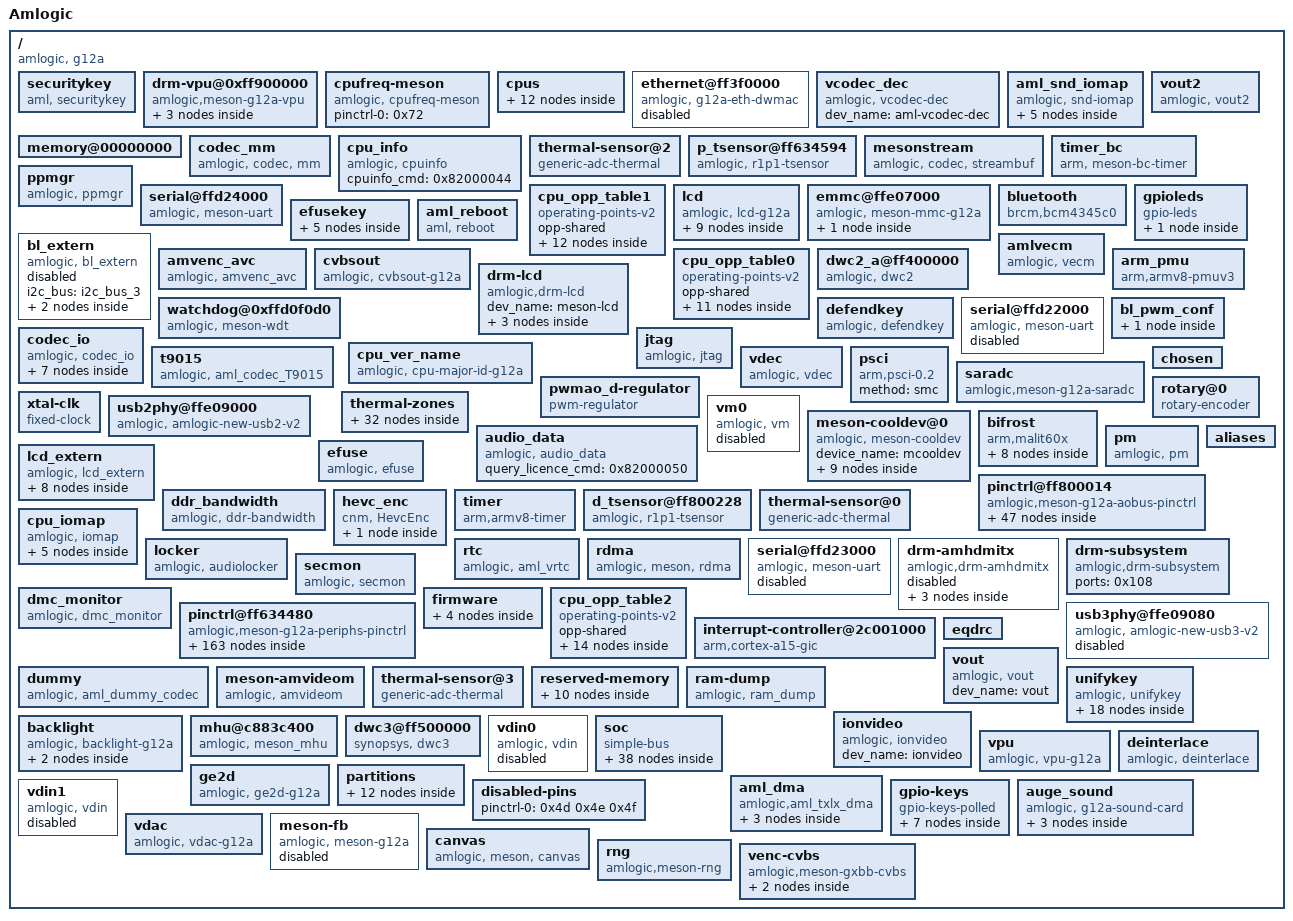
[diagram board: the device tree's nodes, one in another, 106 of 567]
/dts-v1/;

/ {
	model = "Amlogic";
	#address-cells = <0x02>;
	compatible = "amlogic, g12a";
	#size-cells = <0x02>;
	interrupt-parent = <0x01>;
	amlogic-dt-id = "g12a_evt_1g";

	securitykey {
		storage_in_func = <0x82000023>;
		storage_write = <0x82000062>;
		storage_query = <0x82000060>;
		storage_list = <0x82000067>;
		storage_block_func = <0x82000025>;
		storage_remove = <0x82000068>;
		storage_version = <0x8200006c>;
		storage_size_func = <0x82000027>;
		storage_tell = <0x82000063>;
		compatible = "aml, securitykey";
		storage_status = <0x82000065>;
		storage_read = <0x82000061>;
		storage_out_func = <0x82000024>;
		storage_verify = <0x82000064>;
		storage_get_enctype = <0x8200006b>;
		storage_set_enctype = <0x8200006a>;
	};

	drm-vpu@0xff900000 {
		clock-names = "vpu_clkc";
		dma-coherent;
		status = "okay";
		compatible = "amlogic,meson-g12a-vpu";
		memory-region = <0x2a>;
		reg = <0x00 0xff900000 0x00 0x40000 0x00 0xff63c000 0x00 0x2000 0x00 0xff638000 0x00 0x2000>;
		clocks = <0x02 0xc9>;
		reg-names = "base", "hhi", "dmc";
		interrupt-names = "viu-vsync", "viu2-vsync";
		interrupts = <0x00 0x03 0x01 0x00 0x38 0x01>;
		phandle = <0x10c>;

		port {
			#address-cells = <0x01>;
			#size-cells = <0x00>;
			phandle = <0x108>;

			endpoint@1 {
				remote-endpoint = <0x107>;
				reg = <0x01>;
				phandle = <0x105>;
			};

			endpoint@0 {
				remote-endpoint = <0x106>;
				reg = <0x00>;
				phandle = <0x104>;
			};
		};
	};

	cpufreq-meson {
		pinctrl-0 = <0x72>;
		pinctrl-names = "default";
		status = "okay";
		compatible = "amlogic, cpufreq-meson";
	};

	cpus {
		#address-cells = <0x02>;
		#size-cells = <0x00>;
		phandle = <0x77>;

		cpu@1 {
			lospeed_cpufreq_max = <0x708>;
			clock-latency = <0xc350>;
			device_type = "cpu";
			clock-names = "core_clk", "low_freq_clk_parent", "high_freq_clk_parent";
			hispeed_cpufreq_max = <0x834>;
			operating-points-v2 = <0x0d 0x0e 0x0f>;
			compatible = "arm,cortex-a53", "arm,armv8";
			cpu-idle-states = <0x0c>;
			reg = <0x00 0x01>;
			clocks = <0x02 0x17 0x02 0x16 0x02 0x00>;
			enable-method = "psci";
			medspeed_cpufreq_max = <0x774>;
			phandle = <0x09>;
			cpu-supply = <0x10>;
			voltage-tolerance = <0x00>;
			diff_tables_supply;
		};

		cpu@0 {
			lospeed_cpufreq_max = <0x708>;
			clock-latency = <0xc350>;
			device_type = "cpu";
			clock-names = "core_clk", "low_freq_clk_parent", "high_freq_clk_parent";
			hispeed_cpufreq_max = <0x834>;
			operating-points-v2 = <0x0d 0x0e 0x0f>;
			compatible = "arm,cortex-a53", "arm,armv8";
			cpu-idle-states = <0x0c>;
			reg = <0x00 0x00>;
			clocks = <0x02 0x17 0x02 0x16 0x02 0x00>;
			enable-method = "psci";
			medspeed_cpufreq_max = <0x774>;
			phandle = <0x08>;
			cpu-supply = <0x10>;
			voltage-tolerance = <0x00>;
			diff_tables_supply;
		};

		cpu-map {

			cluster0 {
				phandle = <0x78>;

				core2 {
					cpu = <0x0a>;
				};

				core3 {
					cpu = <0x0b>;
				};

				core0 {
					cpu = <0x08>;
				};

				core1 {
					cpu = <0x09>;
				};
			};
		};

		cpu@3 {
			lospeed_cpufreq_max = <0x708>;
			clock-latency = <0xc350>;
			device_type = "cpu";
			clock-names = "core_clk", "low_freq_clk_parent", "high_freq_clk_parent";
			hispeed_cpufreq_max = <0x834>;
			operating-points-v2 = <0x0d 0x0e 0x0f>;
			compatible = "arm,cortex-a53", "arm,armv8";
			cpu-idle-states = <0x0c>;
			reg = <0x00 0x03>;
			clocks = <0x02 0x17 0x02 0x16 0x02 0x00>;
			enable-method = "psci";
			medspeed_cpufreq_max = <0x774>;
			phandle = <0x0b>;
			cpu-supply = <0x10>;
			voltage-tolerance = <0x00>;
			diff_tables_supply;
		};

		idle-states {
			entry-method = "arm,psci-0.2";

			cpu-sleep-0 {
				min-residency-us = <0x3a98>;
				exit-latency-us = <0x1388>;
				compatible = "arm,idle-state";
				entry-latency-us = <0x1388>;
				arm,psci-suspend-param = <0x10000>;
				local-timer-stop;
				phandle = <0x0c>;
			};
		};

		cpu@2 {
			lospeed_cpufreq_max = <0x708>;
			clock-latency = <0xc350>;
			device_type = "cpu";
			clock-names = "core_clk", "low_freq_clk_parent", "high_freq_clk_parent";
			hispeed_cpufreq_max = <0x834>;
			operating-points-v2 = <0x0d 0x0e 0x0f>;
			compatible = "arm,cortex-a53", "arm,armv8";
			cpu-idle-states = <0x0c>;
			reg = <0x00 0x02>;
			clocks = <0x02 0x17 0x02 0x16 0x02 0x00>;
			enable-method = "psci";
			medspeed_cpufreq_max = <0x774>;
			phandle = <0x0a>;
			cpu-supply = <0x10>;
			voltage-tolerance = <0x00>;
			diff_tables_supply;
		};
	};

	ethernet@ff3f0000 {
		clock-names = "ethclk81";
		status = "disabled";
		compatible = "amlogic, g12a-eth-dwmac", "snps,dwmac";
		pll_val = <0x9c0040a 0x927e0000 0xac5f49e5>;
		reg = <0x00 0xff3f0000 0x00 0x10000 0x00 0xff634540 0x00 0x08 0x00 0xff64c000 0x00 0xa0>;
		clocks = <0x02 0x38>;
		reg-names = "eth_base", "eth_cfg", "eth_pll";
		interrupt-names = "macirq";
		analog_val = <0x20200000 0xc000 0x23>;
		interrupts = <0x00 0x08 0x01>;
		phandle = <0x7a>;
	};

	vcodec_dec {
		dev_name = "aml-vcodec-dec";
		status = "okay";
		compatible = "amlogic, vcodec-dec";
	};

	aml_snd_iomap {
		#address-cells = <0x02>;
		status = "okay";
		compatible = "amlogic, snd-iomap";
		ranges;
		#size-cells = <0x02>;

		audiolocker_base {
			reg = <0x00 0xff64a000 0x00 0x2000>;
		};

		pdm_bus {
			reg = <0x00 0xff640000 0x00 0x2000>;
		};

		eqdrc_base {
			reg = <0x00 0xff642800 0x00 0x1800>;
		};

		audiobus_base {
			reg = <0x00 0xff642000 0x00 0x2000>;
		};

		reset_base {
			reg = <0x00 0xffd01000 0x00 0x1000>;
		};
	};

	memory@00000000 {
		device_type = "memory";
		linux,usable-memory = <0x00 0x00 0x00 0x20000000>;
		reg = <0x00 0x00 0x00 0x18000000>;
	};

	__symbols__ {
		ao_i2c_master_pins1 = "/pinctrl@ff800014/ao_i2c_pins1";
		spotify_touch_gpio = "/pinctrl@ff634480/spotify_touch_gpio";
		tdmout_a = "/pinctrl@ff634480/tdmout_a";
		gen_clk_ee_z = "/pinctrl@ff634480/gen_clk_ee_z";
		jtag_apao_pins = "/pinctrl@ff800014/jtag_apao_pin";
		keysn_11 = "/unifykey/key_11";
		cpus = "/cpus";
		uart_A = "/serial@ffd24000";
		p_tsensor = "/p_tsensor@ff634594";
		keysn_14 = "/unifykey/key_14";
		spotify_touch_i2c = "/pinctrl@ff634480/spotify_touch_i2c";
		i2c1_master_pins2 = "/pinctrl@ff634480/i2c1_pins2";
		spotify_disabled_pins_c = "/pinctrl@ff634480/spotify_disabled_pins_c";
		boot_b = "/partitions/boot_b";
		meson_fb = "/meson-fb";
		secmon_reserved = "/reserved-memory/linux,secmon";
		clk12_24_z_pins = "/pinctrl@ff634480/clk12_24_z_pins";
		state_rst_output0 = "/pinctrl@ff634480/rstoutput0";
		a_uart_pins = "/pinctrl@ff634480/a_uart";
		data = "/partitions/data";
		pwm_AO_ab = "/soc/aobus@ff800000/pwm@7000";
		vbmeta_b = "/partitions/vbmeta_b";
		uart_AO_B = "/soc/aobus@ff800000/serial@4000";
		sdio_x_en_pins = "/pinctrl@ff634480/sdio_x_en_pins";
		pwm_cd = "/soc/cbus@ffd00000/pwm@1a000";
		uart_B = "/serial@ffd23000";
		dswitch_on = "/thermal-zones/ddr_thermal/trips/trip-point@0";
		pwm_e_pins = "/pinctrl@ff634480/pwm_e";
		remote_pins = "/pinctrl@ff800014/remote_pin";
		i2c0_master_pins3 = "/pinctrl@ff634480/i2c0_pins3";
		sdio_clk_cmd_pins = "/pinctrl@ff634480/sdio_clk_cmd_pins";
		cpu_opp_table1 = "/cpu_opp_table1";
		lcd = "/lcd";
		cpucore_cool0 = "/meson-cooldev@0/cpucore_cool0";
		meson_cooldev = "/meson-cooldev@0";
		pwm_d_pins1 = "/pinctrl@ff634480/pwm_d_pins1";
		efusekey = "/efusekey";
		external_eth_pins = "/pinctrl@ff634480/external_eth_pins";
		bt_pcontrol = "/thermal-zones/bluetooth_thermal/trips/bt_pcontrol";
		ddr_thermal = "/thermal-zones/ddr_thermal";
		ao_b_uart_pins = "/pinctrl@ff800014/ao_b_uart";
		pcontrol = "/thermal-zones/soc_thermal/trips/trip-point@1";
		cam_dvp_pins = "/pinctrl@ff634480/cam_dvp_pins";
		key_4 = "/efusekey/key_4";
		internal_eth_pins = "/pinctrl@ff634480/internal_eth_pins";
		pwm_d_pins2 = "/pinctrl@ff634480/pwm_d_pins2";
		rt2 = "/thermal-sensor@3";
		meson_suspend = "/pm";
		sdio_x_all_pins = "/pinctrl@ff634480/sdio_x_all_pins";
		b_uart_pins = "/pinctrl@ff634480/b_uart";
		cpufreq_cool0 = "/meson-cooldev@0/cpufreq_cool0";
		cpu_opp_table0 = "/cpu_opp_table0";
		i2c2_master_pins1 = "/pinctrl@ff634480/i2c2_pins1";
		tdmin_a = "/pinctrl@ff634480/tdmin_a";
		pwm_ao_d_pins1 = "/pinctrl@ff800014/pwm_ao_d_pins1";
		spicc0 = "/soc/cbus@ffd00000/spi@13000";
		dram_critical = "/thermal-zones/dram_thermal/trips/dram_critical";
		hdmitx_ddc = "/pinctrl@ff634480/hdmitx_ddc";
		i2c_AO = "/soc/aobus@ff800000/i2c@5000";
		audiolocker = "/locker";
		pwm_ao_a_pins = "/pinctrl@ff800014/pwm_ao_a";
		dummy_codec = "/dummy";
		spicc0_pins_c = "/pinctrl@ff634480/spicc0_pins_c";
		keysn_16 = "/unifykey/key_16";
		CPU3 = "/cpus/cpu@3";
		irblaster_pins = "/pinctrl@ff800014/irblaster_pin";
		vbmeta_a = "/partitions/vbmeta_a";
		defendkey = "/defendkey";
		i2c3 = "/soc/cbus@ffd00000/i2c@1c000";
		key_1 = "/efusekey/key_1";
		keysn_8 = "/unifykey/key_8";
		dvfs666_cfg = "/bifrost/dvfs666_cfg";
		dvfs850_cfg = "/bifrost/dvfs850_cfg";
		uart_AO = "/soc/aobus@ff800000/serial@3000";
		dvfs250_cfg = "/bifrost/dvfs250_cfg";
		rt3 = "/thermal-sensor@0";
		emmc_clk_cmd_pins = "/pinctrl@ff634480/emmc_clk_cmd_pins";
		sd_to_ao_uart_clr_pins = "/pinctrl@ff800014/sd_to_ao_uart_clr_pins";
		spotify_rotary = "/pinctrl@ff634480/spotify_rotary";
		ao_uart_pins = "/pinctrl@ff800014/ao_uart";
		pwm_b_pins2 = "/pinctrl@ff634480/pwm_b_pins2";
		bl_pwm_conf = "/bl_pwm_conf";
		codec_io = "/codec_io";
		key_3 = "/efusekey/key_3";
		sdio_x_clk_cmd_pins = "/pinctrl@ff634480/sdio_x_clk_cmd_pins";
		pwm_c_pins2 = "/pinctrl@ff634480/pwm_c_pins2";
		vm0_cma_reserved = "/reserved-memory/linux,vm0_cma";
		amlogic_codec = "/t9015";
		i2c2 = "/soc/cbus@ffd00000/i2c@1d000";
		dvfs400_cfg = "/bifrost/dvfs400_cfg";
		emmc_conf_pull_done = "/pinctrl@ff634480/emmc_conf_pull_done";
		CPU2 = "/cpus/cpu@2";
		CPU0 = "/cpus/cpu@0";
		sd_all_pins = "/pinctrl@ff634480/sd_all_pins";
		eecec_b = "/pinctrl@ff634480/ee_cecb";
		spotify_disabled_pins_a = "/pinctrl@ff634480/spotify_disabled_pins_a";
		spicc1 = "/soc/cbus@ffd00000/spi@15000";
		mailbox = "/mhu@c883c400";
		ion_cma_reserved = "/reserved-memory/linux,ion-dev";
		sd_clr_all_pins = "/pinctrl@ff634480/sd_clr_all_pins";
		saradc = "/saradc";
		i2c0_master_pins1 = "/pinctrl@ff634480/i2c0_pins1";
		keysn_3 = "/unifykey/key_3";
		spotify_prox_gpio = "/pinctrl@ff634480/spotify_prox_gpio";
		audio_effect = "/eqdrc";
		dtbo_b = "/partitions/dtbo_b";
		system_a = "/partitions/system_a";
		ppmgr_reserved = "/reserved-memory/linux,ppmgr";
		spdifout_a_mute = "/pinctrl@ff800014/spdifout_a_mute";
		spicc0_pins_x = "/pinctrl@ff634480/spicc0_pins_x";
		aocec_a = "/pinctrl@ff800014/ao_ceca";
		spotify_bluetooth_host_wake_bt = "/pinctrl@ff634480/spotify_bluetooth_host_wake_bt";
		gpufreq_cool0 = "/meson-cooldev@0/gpufreq_cool0";
		dvfs800_cfg = "/bifrost/dvfs800_cfg";
		pinctrl_periphs = "/pinctrl@ff634480";
		dvfs500_cfg = "/bifrost/dvfs500_cfg";
		pwm_ao_c_pins1 = "/pinctrl@ff800014/pwm_ao_c_pins1";
		pwm_ab = "/soc/cbus@ffd00000/pwm@1b000";
		periphs = "/soc/periphs@ff634400";
		jtag_apee_pins = "/pinctrl@ff634480/jtag_apee_pin";
		pwm_ao_c_pins2 = "/pinctrl@ff800014/pwm_ao_c_pins2";
		wdt = "/watchdog@0xffd0f0d0";
		vddcpu0 = "/pwmao_d-regulator";
		clkc = "/soc/hiubus@ff63c000/clock-controller@0";
		soc_thermal = "/thermal-zones/soc_thermal";
		keysn_4 = "/unifykey/key_4";
		cbus = "/soc/cbus@ffd00000";
		pwm_a_pins = "/pinctrl@ff634480/pwm_a";
		gpu = "/bifrost";
		keysn_13 = "/unifykey/key_13";
		logo = "/partitions/logo";
		sd_emmc_c = "/emmc@ffe07000";
		pcritical = "/thermal-zones/soc_thermal/trips/trip-point@3";
		ao_to_sd_uart_pins = "/pinctrl@ff634480/ao_to_sd_uart_pins";
		keysn_15 = "/unifykey/key_15";
		spotify_lcd_reset_pin = "/pinctrl@ff634480/spotify_lcd_reset_pin";
		logo_reserved = "/reserved-memory/linux,meson-fb";
		keysn_9 = "/unifykey/key_9";
		keysn_7 = "/unifykey/key_7";
		audio_data = "/audio_data";
		pwm_ao_d_pins3 = "/pinctrl@ff800014/pwm_ao_d_pins3";
		dcritical = "/thermal-zones/ddr_thermal/trips/trip-point@3";
		pcb_pswitchon = "/thermal-zones/pcb_thermal/trips/pcb_pswitchon";
		i2c1_master_pins3 = "/pinctrl@ff634480/i2c1_pins3";
		dwc2_a = "/dwc2_a@ff400000";
		sd_clk_cmd_pins = "/pinctrl@ff634480/sd_clk_cmd_pins";
		key_2 = "/efusekey/key_2";
		efuse = "/efuse";
		sdio_all_pins = "/pinctrl@ff634480/sdio_all_pins";
		aobus = "/soc/aobus@ff800000";
		pwm_b_pins1 = "/pinctrl@ff634480/pwm_b_pins1";
		cluster0 = "/cpus/cpu-map/cluster0";
		keysn_5 = "/unifykey/key_5";
		pwm_c_pins3 = "/pinctrl@ff634480/pwm_c_pins3";
		settings = "/partitions/settings";
		keysn_6 = "/unifykey/key_6";
		spdifin = "/pinctrl@ff634480/spdifin";
		dwc3 = "/dwc3@ff500000";
		aml_pdm = "/soc/audiobus@0xff642000/pdm";
		keysn_17 = "/unifykey/key_17";
		pwm_ao_a_hiz_pins = "/pinctrl@ff800014/pwm_ao_a_hiz";
		i2c_AO_slave = "/soc/aobus@ff800000/i2c_slave@6000";
		pwm_f_pins1 = "/pinctrl@ff634480/pwm_f_pins1";
		audiobus = "/soc/audiobus@0xff642000";
		keysn_2 = "/unifykey/key_2";
		rt1 = "/thermal-sensor@2";
		i2c0_master_pins2 = "/pinctrl@ff634480/i2c0_pins2";
		sd_clr_noall_pins = "/pinctrl@ff634480/sd_clr_noall_pins";
		gpucore_cool0 = "/meson-cooldev@0/gpucore_cool0";
		di_cma_reserved = "/reserved-memory/linux,di_cma";
		pdm_codec = "/dummy";
		spotify_mfi_i2c_pins = "/pinctrl@ff634480/spotify_mfi_i2c_pins";
		pcb_critical = "/thermal-zones/pcb_thermal/trips/pcb_critical";
		dcontrol = "/thermal-zones/ddr_thermal/trips/trip-point@1";
		keysn_10 = "/unifykey/key_10";
		pinctrl_aobus = "/pinctrl@ff800014";
		spotify_disabled_pins_h = "/pinctrl@ff634480/spotify_disabled_pins_h";
		all_nand_pins = "/pinctrl@ff634480/all_nand_pins";
		keysn_1 = "/unifykey/key_1";
		pdmin = "/pinctrl@ff634480/pdmin";
		aocec_b = "/pinctrl@ff800014/ao_cecb";
		secos_reserved = "/reserved-memory/linux,secos";
		misc = "/partitions/misc";
		bl_enable = "/pinctrl@ff634480/bl_enable";
		i2c2_master_pins2 = "/pinctrl@ff634480/i2c2_pins2";
		gpio = "/pinctrl@ff634480/banks@ff6346c0";
		i2c0 = "/soc/cbus@ffd00000/i2c@1f000";
		clkaudio = "/soc/audiobus@0xff642000/audio_clocks";
		cpu_opp_table2 = "/cpu_opp_table2";
		pwm_ao_d_pins2 = "/pinctrl@ff800014/pwm_ao_d_pins2";
		pwm_ao_c_hiz_pins = "/pinctrl@ff800014/pwm_ao_c_hiz";
		xtal = "/xtal-clk";
		bt_critical = "/thermal-zones/bluetooth_thermal/trips/bt_critical";
		boot_a = "/partitions/boot_a";
		hiubus = "/soc/hiubus@ff63c000";
		dram_pswitchon = "/thermal-zones/dram_thermal/trips/dram_pswitchon";
		ethmac = "/ethernet@ff3f0000";
		d_tsensor = "/d_tsensor@ff800228";
		tp_int_input = "/pinctrl@ff634480/eint@0";
		pcb_pcontrol = "/thermal-zones/pcb_thermal/trips/pcb_pcontrol";
		phot = "/thermal-zones/soc_thermal/trips/trip-point@2";
		dtbo_a = "/partitions/dtbo_a";
		keysn_12 = "/unifykey/key_12";
		spotify_bluetooth_bt_wake_host = "/pinctrl@ff634480/spotify_bluetooth_bt_wake_host";
		pswitch_on = "/thermal-zones/soc_thermal/trips/trip-point@0";
		dvfs125_cfg = "/bifrost/clk125_cfg";
		irblaster = "/soc/aobus@ff800000/meson-irblaster@14c";
		eecec_a = "/pinctrl@ff634480/ee_ceca";
		sd_1bit_pins = "/pinctrl@ff634480/sd_1bit_pins";
		system_b = "/partitions/system_b";
		pwm_AO_cd = "/soc/aobus@ff800000/pwm@2000";
		gic = "/interrupt-controller@2c001000";
		sd_to_ao_uart_pins = "/pinctrl@ff800014/sd_to_ao_uart_pins";
		CPU1 = "/cpus/cpu@1";
		hdmitx_hpd_gpio = "/pinctrl@ff634480/hdmitx_hpd_gpio";
		i2c1 = "/soc/cbus@ffd00000/i2c@1e000";
		pwm_c_pins1 = "/pinctrl@ff634480/pwm_c_pins1";
		gpio_ao = "/pinctrl@ff800014/ao-bank@ff800014";
		codec_mm_reserved = "/reserved-memory/linux,codec_mm_reserved";
		uart_C = "/serial@ffd22000";
		spotify_imu_gpio = "/pinctrl@ff634480/spotify_imu_gpio";
		keysn_0 = "/unifykey/key_0";
		vdin0 = "/vdin0";
		internal_gpio_pins = "/pinctrl@ff634480/internal_gpio_pins";
		codec_mm_cma = "/reserved-memory/linux,codec_mm_cma";
		CPU_SLEEP_0 = "/cpus/idle-states/cpu-sleep-0";
		emmc_conf_pull_up = "/pinctrl@ff634480/emmc_conf_pull_up";
		dhot = "/thermal-zones/ddr_thermal/trips/trip-point@2";
		pwm_f_pins2 = "/pinctrl@ff634480/pwm_f_pins2";
		dvfs285_cfg = "/bifrost/dvfs285_cfg";
		key_0 = "/efusekey/key_0";
		partitions = "/partitions";
		usb3_phy_v2 = "/usb3phy@ffe09080";
		pwm_ao_b_pins = "/pinctrl@ff800014/pwm_ao_b";
		ao_i2c_slave_pins = "/pinctrl@ff800014/ao_i2c_slave_pins";
		spicc1_pins = "/pinctrl@ff634480/spicc1_pins";
		aoclkc = "/soc/aobus@ff800000/clock-controller@0";
		pwm_ef = "/soc/cbus@ffd00000/pwm@19000";
		i2c3_master_pins1 = "/pinctrl@ff634480/i2c3_pins1";
		dram_pcontrol = "/thermal-zones/dram_thermal/trips/dram_pcontrol";
		aml_loopback = "/soc/audiobus@0xff642000/loopback";
		ao_i2c_master_pins2 = "/pinctrl@ff800014/ao_i2c_pins2";
		spdifout = "/pinctrl@ff800014/spdifout";
		aml_tdma = "/soc/audiobus@0xff642000/tdma";
		c_uart_pins = "/pinctrl@ff634480/c_uart";
		i2c1_master_pins1 = "/pinctrl@ff634480/i2c1_pins1";
		nand_cs_pins = "/pinctrl@ff634480/nand_cs";
		bt_pswitchon = "/thermal-zones/bluetooth_thermal/trips/bt_pswitchon";
		vdin1 = "/vdin1";
		gpio_intc = "/soc/cbus@ffd00000/interrupt-controller@f080";
		sdio_x_clr_pins = "/pinctrl@ff634480/sdio_x_clr_pins";
		audioresample = "/soc/audiobus@0xff642000/resample";
		canvas = "/canvas";
		spotify_buttons = "/pinctrl@ff634480/spotify_buttons";
		bl_pwm_off_pins = "/pinctrl@ff634480/bl_pwm_off_pin";
		state_rst_output1 = "/pinctrl@ff634480/rstoutput1";
		i2c3_master_pins2 = "/pinctrl@ff634480/i2c3_pins2";
		usb2_phy_v2 = "/usb2phy@ffe09000";
		hdmitx_hpd = "/pinctrl@ff634480/hdmitx_hpd";
	};

	codec_mm {
		dev_name = "codec_mm";
		status = "okay";
		compatible = "amlogic, codec, mm";
		memory-region = <0x51 0x52>;
	};

	vout2 {
		clock-names = "vpu_clkc0", "vpu_clkc";
		dev_name = "vout";
		status = "okay";
		compatible = "amlogic, vout2";
		clocks = <0x02 0xc4 0x02 0xc9>;
	};

	cpu_info {
		status = "okay";
		compatible = "amlogic, cpuinfo";
		cpuinfo_cmd = <0x82000044>;
	};

	thermal-sensor@2 {
		io-channels = <0x50 0x02>;
		temperature-lookup-table = <0x14c08 0x37e 0x13880 0x36e 0x124f8 0x35c 0x11170 0x347 0xfde8 0x32f 0xea60 0x315 0xd6d8 0x2f7 0xc350 0x2d6 0xafc8 0x2b2 0x9c40 0x28a 0x88b8 0x25f 0x7530 0x230 0x61a8 0x200 0x4e20 0x1ce 0x3a98 0x19b 0x2710 0x168 0x1388 0x137 0x00 0x109 0xffffec78 0xdd 0xffffd8f0 0xb6 0xffffc568 0x93 0xffffb1e0 0x75 0xffff9e58 0x5c 0xffff8ad0 0x46 0xffff7748 0x35 0xffff63c0 0x28>;
		compatible = "generic-adc-thermal";
		#thermal-sensor-cells = <0x00>;
		io-channel-names = "sensor-channel";
		phandle = <0x35>;
	};

	p_tsensor@ff634594 {
		cal_type = <0x01>;
		clock-names = "ts_comp";
		cal_d = <0x24c3>;
		rtemp = <0x1c138>;
		cal_c = <0xc57>;
		status = "okay";
		compatible = "amlogic, r1p1-tsensor";
		cal_b = <0x1a8>;
		#thermal-sensor-cells = <0x01>;
		cal_a = <0x144>;
		reg = <0x00 0xff634800 0x00 0x50 0x00 0xff800268 0x00 0x04>;
		clocks = <0x02 0xd6>;
		device_name = "meson-pthermal";
		interrupts = <0x00 0x23 0x00>;
		phandle = <0x2e>;
	};

	mesonstream {
		clock-names = "parser_top", "demux", "ahbarb0", "vdec", "clk_81", "clk_vdec_mux", "clk_hcodec_mux", "clk_hevc_mux", "clk_hevcb_mux";
		dev_name = "mesonstream";
		status = "okay";
		compatible = "amlogic, codec, streambuf";
		clocks = <0x02 0x40 0x02 0x39 0x02 0x43 0x02 0x22 0x02 0x0b 0x02 0xa5 0x02 0xae 0x02 0xb7 0x02 0xc0>;
	};

	timer_bc {
		bit_resolution = <0x00>;
		timer_name = "Meson TimerF";
		clockevent-rating = <0x12c>;
		compatible = "arm, meson-bc-timer";
		bit_mode = <0x0c>;
		reg = <0x00 0xffd0f190 0x00 0x04 0x00 0xffd0f194 0x00 0x04>;
		clockevent-features = <0x23>;
		bit_enable = <0x10>;
		clockevent-shift = <0x14>;
		interrupts = <0x00 0x3c 0x01>;
	};

	ppmgr {
		dev_name = "ppmgr";
		status = "okay";
		compatible = "amlogic, ppmgr";
		memory-region = <0x53>;
	};

	serial@ffd24000 {
		pinctrl-0 = <0x27>;
		clock-names = "clk_uart", "clk_gate";
		fifosize = <0x80>;
		pinctrl-names = "default";
		status = "okay";
		compatible = "amlogic, meson-uart";
		reg = <0x00 0xffd24000 0x00 0x18>;
		clocks = <0x16 0x02 0x2e>;
		interrupts = <0x00 0x1a 0x01>;
		phandle = <0xe1>;
	};

	cpu_opp_table1 {
		opp-shared;
		compatible = "operating-points-v2";
		phandle = <0x0e>;

		opp04 {
			opp-microvolt = <0xb2778>;
			opp-hz = <0x00 0x3b9aca00>;
		};

		opp11 {
			opp-microvolt = <0xf1f18>;
			opp-hz = <0x00 0x71b9c500>;
		};

		opp03 {
			opp-microvolt = <0xb2778>;
			opp-hz = <0x00 0x27c19cc0>;
		};

		opp01 {
			opp-microvolt = <0xb2778>;
			opp-hz = <0x00 0xee6b280>;
		};

		opp06 {
			opp-microvolt = <0xb9ca8>;
			opp-hz = <0x00 0x5353c980>;
		};

		opp08 {
			opp-microvolt = <0xcae18>;
			opp-hz = <0x00 0x5fd82200>;
		};

		opp02 {
			opp-microvolt = <0xb2778>;
			opp-hz = <0x00 0x1dcd6500>;
		};

		opp00 {
			opp-microvolt = <0xb2778>;
			opp-hz = <0x00 0x5f5e100>;
		};

		opp10 {
			opp-microvolt = <0xef808>;
			opp-hz = <0x00 0x6b49d200>;
		};

		opp09 {
			opp-microvolt = <0xd2348>;
			opp-hz = <0x00 0x6590fa00>;
		};

		opp07 {
			opp-microvolt = <0xc11d8>;
			opp-hz = <0x00 0x5a1f4a00>;
		};

		opp05 {
			opp-microvolt = <0xb2778>;
			opp-hz = <0x00 0x47868c00>;
		};
	};

	lcd {
		clock-names = "dsi_host_gate", "dsi_phy_gate", "dsi_meas", "encl_top_gate", "encl_int_gate", "gp0_pll";
		key_valid = <0x00>;
		status = "okay";
		compatible = "amlogic, lcd-g12a";
		lcd_cpu-gpios = <0x15 0x06 0x00>;
		lcd_cpu_gpio_names = "GPIOZ_5";
		reg = <0x00 0xffd07000 0x00 0x400 0x00 0xff644000 0x00 0x200>;
		clocks = <0x02 0x24 0x02 0x31 0x02 0x9a 0x02 0x5d 0x02 0x5f 0x02 0x07>;
		interrupt-names = "vsync", "vsync2";
		pinctrl_version = <0x02>;
		mode = "tablet";
		interrupts = <0x00 0x03 0x01 0x00 0x38 0x01>;
		phandle = <0x100>;

		lcd_3 {
			mipi_attr = <0x04 0x3c0 0x00 0x01 0x00 0x02 0x01 0x00>;
			backlight_index = <0x00>;
			model_name = "TL050FHV02CT";
			power_off_step = <0x02 0x00 0x00 0x00 0x00 0x00 0x00 0x14 0x00 0x01 0x01 0x64 0xff 0x00 0x00 0x00>;
			lcd_timing = <0x05 0x1e 0x00 0x2c 0x6c 0x00>;
			basic_setting = <0x438 0x780 0x465 0x834 0x08 0x41 0x77>;
			clk_attr = <0x00 0x00 0x01 0x70a71c8>;
			dsi_init_on = <0xff 0x00>;
			dsi_init_off = <0xff 0x00>;
			extern_init = <0x03>;
			power_on_step = <0x00 0x01 0x00 0xc8 0x00 0x00 0x01 0x14 0x00 0x00 0x00 0x0a 0x00 0x00 0x01 0x14 0x02 0x00 0x00 0x00 0xff 0x00 0x00 0x00>;
			interface = "mipi";
		};

		lcd_4 {
			mipi_attr = <0x04 0x12c 0x00 0x01 0x00 0x02 0x01 0x00>;
			backlight_index = <0x00>;
			model_name = "TL070WSH27";
			power_off_step = <0x02 0x00 0x00 0x32 0x00 0x00 0x00 0x0a 0x00 0x01 0x01 0x64 0xff 0x00 0x00 0x00>;
			lcd_timing = <0x50 0x64 0x00 0x05 0x14 0x00>;
			basic_setting = <0x400 0x258 0x4e2 0x276 0x08 0x9a 0x56>;
			clk_attr = <0x00 0x00 0x01 0x2d0fa50>;
			dsi_init_on = <0x05 0x01 0x11 0xfd 0x01 0x14 0x05 0x01 0x29 0xfd 0x01 0x14 0xff 0x00>;
			dsi_init_off = <0x05 0x01 0x28 0xfd 0x01 0x0a 0x05 0x01 0x10 0xfd 0x01 0x0a 0xff 0x00>;
			extern_init = <0xff>;
			power_on_step = <0x00 0x01 0x00 0x64 0x00 0x00 0x00 0x0a 0x00 0x00 0x01 0x14 0x02 0x00 0x00 0x00 0xff 0x00 0x00 0x00>;
			interface = "mipi";
		};

		lcd_1 {
			mipi_attr = <0x04 0x168 0x00 0x01 0x00 0x02 0x00 0x00>;
			backlight_index = <0x00>;
			model_name = "TV070WSM";
			power_off_step = <0x02 0x00 0x00 0x00 0x00 0x00 0x00 0x14 0x00 0x01 0x01 0x64 0xff 0x00 0x00 0x00>;
			lcd_timing = <0x18 0x24 0x00 0x02 0x08 0x00>;
			basic_setting = <0x258 0x400 0x2bc 0x41d 0x08 0x5f 0xa3>;
			clk_attr = <0x00 0x00 0x01 0x2a33390>;
			dsi_init_on = <0xff 0x0a 0xf0 0x03 0x00 0x01 0x1e 0xf0 0x03 0x00 0x00 0x0a 0xf0 0x03 0x00 0x01 0x1e 0xfc 0x02 0x04 0x03 0xff 0x00>;
			dsi_init_off = <0xff 0x00>;
			extern_init = <0x01>;
			power_on_step = <0x00 0x01 0x00 0xc8 0x02 0x00 0x00 0x00 0xff 0x00 0x00 0x00>;
			interface = "mipi";
		};

		lcd_5 {
			mipi_attr = <0x04 0x168 0x00 0x01 0x00 0x02 0x00 0x00>;
			backlight_index = <0x00>;
			model_name = "TV070WSM_FT";
			power_off_step = <0x02 0x00 0x00 0x00 0x00 0x00 0x00 0x14 0x00 0x01 0x01 0x64 0xff 0x00 0x00 0x00>;
			lcd_timing = <0x18 0x24 0x00 0x02 0x08 0x00>;
			basic_setting = <0x258 0x400 0x2bc 0x41d 0x08 0x5f 0xa3>;
			clk_attr = <0x00 0x00 0x01 0x2a33390>;
			dsi_init_on = <0xff 0x0a 0xf0 0x03 0x00 0x01 0x1e 0xf0 0x03 0x00 0x00 0x0a 0xf0 0x03 0x00 0x01 0x1e 0xfc 0x02 0x04 0x03 0xff 0x00>;
			dsi_init_off = <0xff 0x00>;
			extern_init = <0x04>;
			power_on_step = <0x00 0x01 0x00 0xc8 0x02 0x00 0x00 0x00 0xff 0x00 0x00 0x00>;
			interface = "mipi";
		};

		lcd_8 {
			mipi_attr = <0x02 0x2a0 0x00 0x01 0x00 0x02 0x01 0x00>;
			backlight_index = <0x00>;
			model_name = "ST7701S";
			power_off_step = <0x02 0x00 0x00 0x96 0x00 0x00 0x00 0x78 0xff 0x00 0x00 0x00>;
			lcd_timing = <0x0a 0x1e 0x00 0x06 0x14 0x00>;
			basic_setting = <0x1e0 0x320 0x226 0x34e 0x10 0x34 0x56>;
			clk_attr = <0x00 0x00 0x01 0x1a9feb0>;
			dsi_init_on = <0x05 0x01 0x11 0xfd 0x01 0x78 0x05 0x01 0x29 0xff 0xff>;
			dsi_init_off = <0x05 0x01 0x28 0xfd 0x01 0x0a 0x05 0x01 0x10 0xff 0xff>;
			extern_init = <0x07>;
			power_on_step = <0x00 0x00 0x01 0x01 0x00 0x00 0x00 0x0a 0x00 0x00 0x01 0x78 0x02 0x00 0x00 0xc8 0xff 0x00 0x00 0x00>;
			interface = "mipi";
		};

		lcd_7 {
			mipi_attr = <0x02 0x00 0x00 0x01 0x00 0x02 0x01 0x00>;
			backlight_index = <0x00>;
			model_name = "ILI9806E";
			power_off_step = <0x02 0x00 0x00 0x96 0x00 0x00 0x00 0x78 0xff 0x00 0x00 0x00>;
			lcd_timing = <0x0a 0x32 0x00 0x04 0x14 0x00>;
			basic_setting = <0x1e0 0x320 0x276 0x344 0x10 0x33 0x56>;
			clk_attr = <0x00 0x00 0x01 0x1e230a0>;
			dsi_init_on = <0x05 0x01 0x11 0xfd 0x01 0x78 0x05 0x01 0x29 0xff 0xff>;
			dsi_init_off = <0x05 0x01 0x28 0xfd 0x01 0x0a 0x05 0x01 0x10 0xff 0xff>;
			extern_init = <0x06>;
			power_on_step = <0x00 0x00 0x01 0x01 0x00 0x00 0x00 0x0a 0x00 0x00 0x01 0x78 0x02 0x00 0x00 0xc8 0xff 0x00 0x00 0x00>;
			interface = "mipi";
		};

		lcd_6 {
			mipi_attr = <0x04 0x190 0x00 0x01 0x00 0x02 0x00 0x00>;
			backlight_index = <0x00>;
			model_name = "P070ACB_FT";
			power_off_step = <0x02 0x00 0x00 0x00 0x00 0x00 0x00 0x14 0x00 0x01 0x01 0x64 0xff 0x00 0x00 0x00>;
			lcd_timing = <0x0a 0x50 0x00 0x06 0x14 0x00>;
			basic_setting = <0x258 0x400 0x302 0x42e 0x08 0x03 0x05>;
			clk_attr = <0x00 0x00 0x01 0x2f24d90>;
			dsi_init_on = <0xff 0x0a 0xf0 0x03 0x00 0x01 0x1e 0xf0 0x03 0x00 0x00 0x0a 0xf0 0x03 0x00 0x01 0x1e 0xfc 0x02 0x04 0x03 0xff 0x00>;
			dsi_init_off = <0xff 0x00>;
			extern_init = <0x05>;
			power_on_step = <0x00 0x01 0x00 0xc8 0x02 0x00 0x00 0x00 0xff 0x00 0x00 0x00>;
			interface = "mipi";
		};

		lcd_0 {
			mipi_attr = <0x04 0x226 0x00 0x01 0x00 0x02 0x01 0x00>;
			backlight_index = <0x00>;
			model_name = "B080XAN01";
			power_off_step = <0x02 0x00 0x00 0x32 0x00 0x00 0x00 0x0a 0x00 0x01 0x01 0x64 0xff 0x00 0x00 0x00>;
			lcd_timing = <0x40 0x38 0x00 0x32 0x1e 0x00>;
			basic_setting = <0x300 0x400 0x3b4 0x474 0x08 0x77 0x9f>;
			clk_attr = <0x00 0x00 0x01 0x3dd6dc0>;
			dsi_init_on = <0x05 0x01 0x11 0xfd 0x01 0x14 0x05 0x01 0x29 0xfd 0x01 0x14 0xff 0x00>;
			dsi_init_off = <0x05 0x01 0x28 0xfd 0x01 0x0a 0x05 0x01 0x10 0xfd 0x01 0x0a 0xff 0x00>;
			extern_init = <0xff>;
			power_on_step = <0x00 0x01 0x00 0x64 0x00 0x00 0x00 0x0a 0x00 0x00 0x01 0x14 0x02 0x00 0x00 0x00 0xff 0x00 0x00 0x00>;
			interface = "mipi";
		};

		lcd_2 {
			mipi_attr = <0x04 0x190 0x00 0x01 0x00 0x02 0x00 0x00>;
			backlight_index = <0x00>;
			model_name = "P070ACB";
			power_off_step = <0x02 0x00 0x00 0x00 0x00 0x00 0x00 0x14 0x00 0x01 0x01 0x64 0xff 0x00 0x00 0x00>;
			lcd_timing = <0x18 0x24 0x00 0x0a 0x50 0x00>;
			basic_setting = <0x258 0x400 0x2a8 0x4aa 0x08 0x03 0x05>;
			clk_attr = <0x00 0x00 0x01 0x2e755c0>;
			dsi_init_on = <0xff 0x0a 0xf0 0x03 0x00 0x01 0x1e 0xf0 0x03 0x00 0x00 0x0a 0xf0 0x03 0x00 0x01 0x1e 0xfc 0x02 0x04 0x03 0xff 0x00>;
			dsi_init_off = <0xff 0x00>;
			extern_init = <0x02>;
			power_on_step = <0x00 0x01 0x00 0xc8 0x02 0x00 0x00 0x00 0xff 0x00 0x00 0x00>;
			interface = "mipi";
		};
	};

	emmc@ffe07000 {
		pinctrl-0 = <0x2b>;
		clock-names = "core", "clkin0", "clkin1", "clkin2", "xtal";
		pinctrl-names = "emmc_clk_cmd_pins", "emmc_all_pins";
		cap-mmc-highspeed;
		status = "okay";
		compatible = "amlogic, meson-mmc-g12a";
		reg = <0x00 0xffe07000 0x00 0x800>;
		clocks = <0x02 0x35 0x02 0x72 0x02 0x02 0x02 0x05 0x16>;
		disable-wp;
		max-frequency = <0xbebc200>;
		cap-sd-highspeed;
		bus-width = <0x08>;
		interrupts = <0x00 0xbf 0x01>;
		pinctrl-1 = <0x2c 0x2d>;
		phandle = <0xe9>;
		non-removable;

		emmc {
			hw_reset = <0x15 0x26 0x00>;
			calc_f = <0x01>;
			f_max = <0xbebc200>;
			caps2 = "MMC_CAP2_HS200";
			co_phase = <0x03>;
			caps = "MMC_CAP_8_BIT_DATA", "MMC_CAP_MMC_HIGHSPEED", "MMC_CAP_SD_HIGHSPEED", "MMC_CAP_NONREMOVABLE", "MMC_CAP_HW_RESET", "MMC_CAP_ERASE", "MMC_CAP_CMD23";
			pinname = "emmc";
			tx_delay = <0x00>;
			max_req_size = <0x20000>;
			f_min = <0x61a80>;
			card_type = <0x01>;
			ocr_avail = <0x200080>;
			gpio_dat3 = <0x15 0x1d 0x00>;
		};
	};

	bluetooth {
		max-speed = <0x2dc6c0>;
		compatible = "brcm,bcm4345c0";
		host-wakeup-gpios = <0x15 0x48 0x01>;
		device-wakeup-gpios = <0x15 0x49 0x01>;
	};

	gpioleds {
		status = "okay";
		compatible = "gpio-leds";

		sys_led {
			label = "sys_led";
			default-state = "on";
			gpios = <0x4a 0x05 0x00>;
		};
	};

	efusekey {
		key4 = <0x6c>;
		keynum = <0x05>;
		key3 = <0x6b>;
		key1 = <0x69>;
		phandle = <0x39>;
		key2 = <0x6a>;
		key0 = <0x68>;

		key_4 {
			size = <0x0f>;
			offset = <0x22>;
			keyname = "f_serial";
			phandle = <0x6c>;
		};

		key_1 {
			size = <0x06>;
			offset = <0x06>;
			keyname = "mac_bt";
			phandle = <0x69>;
		};

		key_3 {
			size = <0x10>;
			offset = <0x12>;
			keyname = "usid";
			phandle = <0x6b>;
		};

		key_2 {
			size = <0x06>;
			offset = <0x0c>;
			keyname = "mac_wifi";
			phandle = <0x6a>;
		};

		key_0 {
			size = <0x06>;
			offset = <0x00>;
			keyname = "mac";
			phandle = <0x68>;
		};
	};

	bl_extern {
		status = "disabled";
		compatible = "amlogic, bl_extern";
		i2c_bus = "i2c_bus_3";

		extern_1 {
			index = <0x01>;
			dim_max_min = <0xff 0x0a>;
			extern_name = "mipi_lt070me05";
			type = <0x02>;
		};

		extern_0 {
			index = <0x00>;
			dim_max_min = <0xff 0x0a>;
			i2c_address = <0x2c>;
			extern_name = "i2c_lp8556";
			type = <0x00>;
		};
	};

	amvenc_avc {
		dev_name = "amvenc_avc";
		status = "okay";
		compatible = "amlogic, amvenc_avc";
		interrupt-names = "mailbox_2";
		interrupts = <0x00 0x2d 0x01>;
	};

	aml_reboot {
		sys_poweroff = <0x84000008>;
		sys_reset = <0x84000009>;
		compatible = "aml, reboot";
	};

	cvbsout {
		clk_path = <0x00>;
		performance_sarft = <0x1bf0 0x09 0x1b56 0x333 0x1b12 0x00 0x1b05 0x09 0x1c59 0xfc48 0xffff 0x00>;
		clock-names = "venci_top_gate", "venci_0_gate", "venci_1_gate", "vdac_clk_gate";
		dev_name = "cvbsout";
		status = "okay";
		compatible = "amlogic, cvbsout-g12a";
		performance_revB_telecom = <0x1bf0 0x09 0x1b56 0x546 0x1b12 0x8080 0x1b05 0x09 0x1c59 0xf850 0xffff 0x00>;
		clocks = <0x02 0x55 0x02 0x4e 0x02 0x4f 0x02 0x57>;
		performance = <0x1bf0 0x09 0x1b56 0x333 0x1b12 0x8080 0x1b05 0xfd 0x1c59 0xf850 0xffff 0x00>;
	};

	cpu_opp_table0 {
		opp-shared;
		compatible = "operating-points-v2";
		phandle = <0x0d>;

		opp04 {
			opp-microvolt = <0xb2778>;
			opp-hz = <0x00 0x3b9aca00>;
		};

		opp03 {
			opp-microvolt = <0xb2778>;
			opp-hz = <0x00 0x27c19cc0>;
		};

		opp01 {
			opp-microvolt = <0xb2778>;
			opp-hz = <0x00 0xee6b280>;
		};

		opp06 {
			opp-microvolt = <0xb9ca8>;
			opp-hz = <0x00 0x5353c980>;
		};

		opp08 {
			opp-microvolt = <0xcae18>;
			opp-hz = <0x00 0x5fd82200>;
		};

		opp02 {
			opp-microvolt = <0xb2778>;
			opp-hz = <0x00 0x1dcd6500>;
		};

		opp00 {
			opp-microvolt = <0xb2778>;
			opp-hz = <0x00 0x5f5e100>;
		};

		opp10 {
			opp-microvolt = <0xef808>;
			opp-hz = <0x00 0x6b49d200>;
		};

		opp09 {
			opp-microvolt = <0xd2348>;
			opp-hz = <0x00 0x6590fa00>;
		};

		opp07 {
			opp-microvolt = <0xc11d8>;
			opp-hz = <0x00 0x5a1f4a00>;
		};

		opp05 {
			opp-microvolt = <0xb2778>;
			opp-hz = <0x00 0x47868c00>;
		};
	};

	dwc2_a@ff400000 {
		phy-interface = <0x00>;
		port-type = <0x02>;
		clock-names = "usb_general", "usb1";
		phy-reg = <0xffe09000>;
		port-speed = <0x00>;
		port-id-mode = <0x00>;
		status = "okay";
		compatible = "amlogic, dwc2";
		cpu-type = "v2";
		phy-reg-size = <0xa0>;
		pl-periph-id = <0x00>;
		controller-type = <0x03>;
		reg = <0x00 0xff400000 0x00 0x40000>;
		usb-fifo = <0x2d8>;
		clocks = <0x02 0x41 0x02 0x49>;
		device_name = "dwc2_a";
		port-config = <0x00>;
		clock-src = "usb0";
		interrupts = <0x00 0x1f 0x04>;
		phandle = <0xc8>;
		port-id = <0x00>;
		port-dma = <0x00>;
	};

	amlvecm {
		dev_name = "aml_vecm";
		wb_en = <0x00>;
		tx_op_color_primary = <0x00>;
		status = "okay";
		compatible = "amlogic, vecm";
		cm_en = <0x00>;
		gamma_en = <0x00>;
	};

	arm_pmu {
		compatible = "arm,armv8-pmuv3";
		reg = <0x00 0xff634680 0x00 0x04>;
		max-wait-cnt = <0x2710>;
		cpumasks = <0x0f>;
		relax-timer-ns = <0x989680>;
		interrupts = <0x00 0x89 0x04>;
	};

	drm-lcd {
		dev_name = "meson-lcd";
		status = "okay";
		compatible = "amlogic,drm-lcd";
		phandle = <0x10b>;

		ports {

			port {
				#address-cells = <0x01>;
				#size-cells = <0x00>;

				endpoint@0 {
					remote-endpoint = <0x105>;
					reg = <0x00>;
					phandle = <0x107>;
				};
			};
		};
	};

	watchdog@0xffd0f0d0 {
		firmware_timeout = <0x06>;
		clock-names = "xtal";
		shutdown_timeout = <0x0a>;
		status = "okay";
		compatible = "amlogic, meson-wdt";
		reset_watchdog_method = <0x01>;
		default_timeout = <0x0a>;
		suspend_timeout = <0x06>;
		reg = <0x00 0xffd0f0d0 0x00 0x10>;
		reset_watchdog_time = <0x02>;
		clocks = <0x16>;
		phandle = <0xc9>;
	};

	defendkey {
		status = "okay";
		compatible = "amlogic, defendkey";
		mem_size = <0x00 0x100000>;
		reg = <0x00 0xff630218 0x00 0x04>;
		phandle = <0xfd>;
	};

	serial@ffd22000 {
		pinctrl-0 = <0x29>;
		clock-names = "clk_uart", "clk_gate";
		fifosize = <0x40>;
		pinctrl-names = "default";
		status = "disabled";
		compatible = "amlogic, meson-uart";
		reg = <0x00 0xffd22000 0x00 0x18>;
		clocks = <0x16 0x02 0x3c>;
		interrupts = <0x00 0x5d 0x01>;
		phandle = <0xe3>;
	};

	cpu_ver_name {
		compatible = "amlogic, cpu-major-id-g12a";
	};

	bl_pwm_conf {
		phandle = <0x48>;

		pwm_channel_0 {
			pwm_port_index = <0x05>;
			pwms = <0x49 0x01 0x7558 0x00>;
		};
	};

	codec_io {
		#address-cells = <0x02>;
		status = "okay";
		compatible = "amlogic, codec_io";
		ranges;
		#size-cells = <0x02>;
		phandle = <0xe7>;

		io_dmc_base {
			reg = <0x00 0xff638000 0x00 0x2000>;
		};

		io_efuse_base {
			reg = <0x00 0xff630000 0x00 0x2000>;
		};

		io_hiubus_base {
			reg = <0x00 0xff63c000 0x00 0x2000>;
		};

		io_cbus_base {
			reg = <0x00 0xffd00000 0x00 0x100000>;
		};

		io_vcbus_base {
			reg = <0x00 0xff900000 0x00 0x40000>;
		};

		io_dos_base {
			reg = <0x00 0xff620000 0x00 0x10000>;
		};

		io_aobus_base {
			reg = <0x00 0xff800000 0x00 0x10000>;
		};
	};

	jtag {
		pinctrl-0 = <0x17>;
		pinctrl-names = "jtag_apao_pins", "jtag_apee_pins";
		status = "okay";
		compatible = "amlogic, jtag";
		select = "disable";
		pinctrl-1 = <0x18>;
	};

	t9015 {
		#sound-dai-cells = <0x00>;
		status = "okay";
		compatible = "amlogic, aml_codec_T9015";
		reg = <0x00 0xff632000 0x00 0x2000>;
		is_auge_used = <0x01>;
		tdmout_index = <0x01>;
		phandle = <0x6e>;
	};

	vdec {
		dev_name = "vdec.0";
		status = "okay";
		compatible = "amlogic, vdec";
		interrupt-names = "vsync", "demux", "parser", "mailbox_0", "mailbox_1", "mailbox_2";
		interrupts = <0x00 0x03 0x01 0x00 0x17 0x01 0x00 0x20 0x01 0x00 0x2b 0x01 0x00 0x2c 0x01 0x00 0x2d 0x01>;
	};

	psci {
		compatible = "arm,psci-0.2";
		method = "smc";
	};

	saradc {
		#io-channel-cells = <0x01>;
		clock-names = "xtal", "saradc_clk";
		status = "okay";
		compatible = "amlogic,meson-g12a-saradc";
		reg = <0x00 0xff809000 0x00 0x48>;
		clocks = <0x16 0x02 0x103>;
		interrupts = <0x00 0xc8 0x01>;
		phandle = <0x50>;
	};

	pwmao_d-regulator {
		regulator-max-microvolt = <0xf9830>;
		status = "okay";
		compatible = "pwm-regulator";
		voltage-table = <0xf9830 0x00 0xf6d38 0x03 0xf4628 0x06 0xf1f18 0x0a 0xef808 0x0d 0xed0f8 0x10 0xea9e8 0x14 0xe82d8 0x17 0xe5bc8 0x1a 0xe34b8 0x1e 0xe0da8 0x21 0xde698 0x24 0xdbf88 0x28 0xd9878 0x2b 0xd7168 0x2e 0xd4a58 0x32 0xd2348 0x35 0xcfc38 0x38 0xcd528 0x3c 0xcae18 0x3f 0xc8708 0x43 0xc5ff8 0x46 0xc38e8 0x49 0xc11d8 0x4c 0xbeac8 0x50 0xbc3b8 0x53 0xb9ca8 0x56 0xb7598 0x5a 0xb4e88 0x5d 0xb2778 0x60 0xb0068 0x64>;
		regulator-min-microvolt = <0xb0068>;
		max-duty-cycle = <0x4e2>;
		regulator-always-on;
		pwms = <0x38 0x01 0x4e2 0x00>;
		regulator-name = "vddcpu0";
		phandle = <0x10>;
	};

	chosen {
		linux,initrd-end = <0x00 0x13e2c800>;
		bootargs = "init=/sbin/pre-init ramoops.pstore_en=1 ramoops.record_size=0x8000 ramoops.console_size=0x4000 rootfstype=ext4 console=ttyS0,115200n8 no_console_suspend earlycon=aml-uart,0xff803000 root=/dev/mmcblk0p14 ro rootwait skip_initramfs reboot_mode_android=normal logo=osd0,loaded,0x1f800000 fb_width=480 fb_height=800 vout=panel,enable panel_type=lcd_8 frac_rate_policy=1 osd_reverse=0 video_reverse=0 irq_check_en=0 androidboot.selinux=enforcing androidboot.firstboot=0 jtag=disable uboot_version=v1.0-74-gfd61b37038 androidboot.hardware=amlogic androidboot.slot_suffix=_a ";
		linux,initrd-start = <0x00 0x13e2c000>;
	};

	rotary@0 {
		rotary-encoder,steps-per-period = <0x02>;
		linux,axis = <0x06>;
		pinctrl-0 = <0x4c>;
		rotary-encoder,encoding = "gray";
		pinctrl-names = "default";
		compatible = "rotary-encoder";
		wakeup-source = <0x00>;
		gpios = <0x15 0x09 0x01 0x15 0x0a 0x01>;
		rotary-encoder,relative-axis;
	};

	thermal-zones {

		ddr_thermal {
			polling-delay = <0x3e8>;
			thermal-sensors = <0x34 0x01>;
			sustainable-power = <0x866>;
			polling-delay-passive = <0x64>;
			phandle = <0xef>;

			trips {

				trip-point@3 {
					hysteresis = <0x3e8>;
					temperature = <0x1adb0>;
					type = "critical";
					phandle = <0xf3>;
				};

				trip-point@2 {
					hysteresis = <0x1388>;
					temperature = <0x14c08>;
					type = "hot";
					phandle = <0xf2>;
				};

				trip-point@0 {
					hysteresis = <0x1388>;
					temperature = <0xea60>;
					type = "passive";
					phandle = <0xf0>;
				};

				trip-point@1 {
					hysteresis = <0x1388>;
					temperature = <0x124f8>;
					type = "passive";
					phandle = <0xf1>;
				};
			};
		};

		pcb_thermal {
			polling-delay = <0x3a98>;
			thermal-sensors = <0x37>;
			polling-delay-passive = <0x3e8>;

			trips {

				pcb_pswitchon {
					hysteresis = <0x3e8>;
					temperature = <0xea60>;
					type = "passive";
					phandle = <0xfa>;
				};

				pcb_critical {
					hysteresis = <0x3e8>;
					temperature = <0x14c08>;
					type = "critical";
					phandle = <0xfc>;
				};

				pcb_pcontrol {
					hysteresis = <0x1388>;
					temperature = <0x124f8>;
					type = "passive";
					phandle = <0xfb>;
				};
			};
		};

		soc_thermal {
			polling-delay = <0x3e8>;
			thermal-sensors = <0x2e 0x00>;
			sustainable-power = <0x5b4>;
			polling-delay-passive = <0x64>;
			phandle = <0xeb>;

			cooling-maps {

				gpufreq_cooling_map {
					trip = <0x2f>;
					contribution = <0x400>;
					cooling-device = <0x32 0x00 0x04>;
				};

				cpucore_cooling_map {
					trip = <0x2f>;
					contribution = <0x400>;
					cooling-device = <0x31 0x00 0x03>;
				};

				gpucore_cooling_map {
					trip = <0x2f>;
					contribution = <0x400>;
					cooling-device = <0x33 0x00 0x02>;
				};

				cpufreq_cooling_map {
					trip = <0x2f>;
					contribution = <0x400>;
					cooling-device = <0x30 0x00 0x04>;
				};
			};

			trips {

				trip-point@3 {
					hysteresis = <0x3e8>;
					temperature = <0x1adb0>;
					type = "critical";
					phandle = <0xee>;
				};

				trip-point@2 {
					hysteresis = <0x1388>;
					temperature = <0x17318>;
					type = "hot";
					phandle = <0xed>;
				};

				trip-point@0 {
					hysteresis = <0x1388>;
					temperature = <0xea60>;
					type = "passive";
					phandle = <0xec>;
				};

				trip-point@1 {
					hysteresis = <0x1388>;
					temperature = <0x14c08>;
					type = "passive";
					phandle = <0x2f>;
				};
			};
		};

		dram_thermal {
			polling-delay = <0x3a98>;
			thermal-sensors = <0x36>;
			polling-delay-passive = <0x3e8>;

			trips {

				dram_critical {
					hysteresis = <0x3e8>;
					temperature = <0x14c08>;
					type = "critical";
					phandle = <0xf9>;
				};

				dram_pswitchon {
					hysteresis = <0x3e8>;
					temperature = <0xea60>;
					type = "passive";
					phandle = <0xf7>;
				};

				dram_pcontrol {
					hysteresis = <0x1388>;
					temperature = <0x124f8>;
					type = "passive";
					phandle = <0xf8>;
				};
			};
		};

		bluetooth_thermal {
			polling-delay = <0x3a98>;
			thermal-sensors = <0x35>;
			polling-delay-passive = <0x3e8>;

			trips {

				bt_pcontrol {
					hysteresis = <0x1388>;
					temperature = <0x124f8>;
					type = "passive";
					phandle = <0xf5>;
				};

				bt_critical {
					hysteresis = <0x3e8>;
					temperature = <0x14c08>;
					type = "critical";
					phandle = <0xf6>;
				};

				bt_pswitchon {
					hysteresis = <0x3e8>;
					temperature = <0xea60>;
					type = "passive";
					phandle = <0xf4>;
				};
			};
		};
	};

	xtal-clk {
		clock-output-names = "xtal";
		#clock-cells = <0x00>;
		compatible = "fixed-clock";
		clock-frequency = <0x16e3600>;
		phandle = <0x16>;
	};

	usb2phy@ffe09000 {
		pll-setting-3 = <0xac5f49e5>;
		pll-setting-5 = <0x8000fff>;
		pll-setting-6 = <0x78000>;
		status = "okay";
		pll-setting-7 = <0xe0004>;
		compatible = "amlogic, amlogic-new-usb2-v2";
		reg = <0x00 0xffe09000 0x00 0x80 0x00 0xffd01008 0x00 0x100 0x00 0xff636000 0x00 0x2000 0x00 0xff63a000 0x00 0x2000>;
		pll-setting-8 = <0xe000c>;
		pll-setting-1 = <0x9400414>;
		pll-setting-2 = <0x927e0000>;
		portnum = <0x02>;
		phandle = <0x13>;
		pll-setting-4 = <0xfe18>;
	};

	vm0 {
		vm_id = <0x00>;
		dev_name = "vm0";
		status = "disabled";
		compatible = "amlogic, vm";
		memory-region = <0x55>;
	};

	meson-cooldev@0 {
		status = "okay";
		compatible = "amlogic, meson-cooldev";
		device_name = "mcooldev";
		phandle = <0xea>;

		cpucore_cool0 {
			#cooling-cells = <0x02>;
			phandle = <0x31>;
		};

		cpufreq_cool0 {
			#cooling-cells = <0x02>;
			phandle = <0x30>;
		};

		gpufreq_cool0 {
			#cooling-cells = <0x02>;
			phandle = <0x32>;
		};

		gpucore_cool0 {
			#cooling-cells = <0x02>;
			phandle = <0x33>;
		};

		cooling_devices {

			gpufreq_cool {
				min_state = <0x190>;
				dyn_coeff = <0x166>;
				device_type = "gpufreq";
				node_name = "gpufreq_cool0";
				gpu_pp = <0x02>;
				cluster_id = <0x00>;
			};

			cpucore_cool_cluster0 {
				min_state = <0x01>;
				dyn_coeff = <0x00>;
				device_type = "cpucore";
				node_name = "cpucore_cool0";
				cluster_id = <0x00>;
			};

			cpufreq_cool_cluster0 {
				min_state = <0xf4240>;
				dyn_coeff = <0x73>;
				device_type = "cpufreq";
				node_name = "cpufreq_cool0";
				cluster_id = <0x00>;
			};

			gpucore_cool {
				min_state = <0x01>;
				dyn_coeff = <0x00>;
				device_type = "gpucore";
				node_name = "gpucore_cool0";
				cluster_id = <0x00>;
			};
		};
	};

	audio_data {
		query_licence_cmd = <0x82000050>;
		status = "okay";
		compatible = "amlogic, audio_data";
		phandle = <0xc6>;
	};

	bifrost {
		clock-names = "gpu_mux", "gp0_pll";
		tbl = <0x03 0x04 0x05 0x06 0x07 0x07>;
		sc_mpp = <0x01>;
		#cooling-cells = <0x02>;
		compatible = "arm,malit60x", "arm,malit6xx", "arm,mali-midgard";
		reg = <0x00 0xffe40000 0x00 0x4000 0x00 0xffd01000 0x00 0x1000 0x00 0xff800000 0x00 0x1000 0x00 0xff63c000 0x00 0x1000 0x00 0xffd01000 0x00 0x1000>;
		clocks = <0x02 0x83 0x02 0x07>;
		interrupt-parent = <0x01>;
		interrupt-names = "GPU", "MMU", "JOB";
		num_of_pp = <0x02>;
		interrupts = <0x00 0xa0 0x04 0x00 0xa1 0x04 0x00 0xa2 0x04>;
		phandle = <0x73>;

		dvfs666_cfg {
			keep_count = <0x05>;
			voltage = <0x47e>;
			clkp_freq = <0x27bc86aa>;
			clk_reg = <0x800>;
			clk_parent = "fclk_div3";
			threshold = <0xd2 0xec>;
			clk_freq = <0x27bc86aa>;
			phandle = <0x06>;
		};

		dvfs850_cfg {
			keep_count = <0x05>;
			voltage = <0x47e>;
			clkp_freq = <0x326cef80>;
			clk_reg = <0x200>;
			clk_parent = "gp0_pll";
			threshold = <0xe6 0xff>;
			clk_freq = <0x326cef80>;
			phandle = <0x07>;
		};

		dvfs250_cfg {
			keep_count = <0x05>;
			voltage = <0x47e>;
			clkp_freq = <0x1dcd6500>;
			clk_reg = <0xa01>;
			clk_parent = "fclk_div4";
			threshold = <0x50 0xaa>;
			clk_freq = <0xee6b280>;
			phandle = <0x75>;
		};

		dvfs400_cfg {
			keep_count = <0x05>;
			voltage = <0x47e>;
			clkp_freq = <0x17d78400>;
			clk_reg = <0xc00>;
			clk_parent = "fclk_div5";
			threshold = <0x98 0xcf>;
			clk_freq = <0x17d78400>;
			phandle = <0x04>;
		};

		dvfs800_cfg {
			keep_count = <0x05>;
			voltage = <0x47e>;
			clkp_freq = <0x2faf0800>;
			clk_reg = <0x600>;
			clk_parent = "fclk_div2p5";
			threshold = <0xe6 0xff>;
			clk_freq = <0x2faf0800>;
			phandle = <0x76>;
		};

		dvfs500_cfg {
			keep_count = <0x05>;
			voltage = <0x47e>;
			clkp_freq = <0x1dcd6500>;
			clk_reg = <0xa00>;
			clk_parent = "fclk_div4";
			threshold = <0xb4 0xdc>;
			clk_freq = <0x1dcd6500>;
			phandle = <0x05>;
		};

		clk125_cfg {
			keep_count = <0x05>;
			voltage = <0x47e>;
			clkp_freq = <0x1dcd6500>;
			clk_reg = <0xa03>;
			clk_parent = "fclk_div4";
			threshold = <0x1e 0x78>;
			clk_freq = <0x7735940>;
			phandle = <0x74>;
		};

		dvfs285_cfg {
			keep_count = <0x05>;
			voltage = <0x47e>;
			clkp_freq = <0x1107a76d>;
			clk_reg = <0xe00>;
			clk_parent = "fclk_div7";
			threshold = <0x64 0xbe>;
			clk_freq = <0x1107a76d>;
			phandle = <0x03>;
		};
	};

	pm {
		status = "okay";
		compatible = "amlogic, pm";
		reg = <0x00 0xff8000a8 0x00 0x04 0x00 0xff80023c 0x00 0x04>;
		device_name = "aml_pm";
		phandle = <0x79>;
	};

	efuse {
		clock-names = "efuse_clk";
		key = <0x39>;
		status = "okay";
		compatible = "amlogic, efuse";
		get_max_cmd = <0x82000033>;
		clocks = <0x02 0x61>;
		write_cmd = <0x82000031>;
		read_cmd = <0x82000030>;
		phandle = <0xfe>;
	};

	aliases {
		serial1 = "/serial@ffd24000";
		serial3 = "/serial@ffd22000";
		i2c3 = "/soc/cbus@ffd00000/i2c@1c000";
		i2c2 = "/soc/cbus@ffd00000/i2c@1d000";
		serial2 = "/serial@ffd23000";
		serial0 = "/soc/aobus@ff800000/serial@3000";
		tsensor1 = "/d_tsensor@ff800228";
		i2c0 = "/soc/cbus@ffd00000/i2c@1f000";
		tsensor0 = "/p_tsensor@ff634594";
		i2c4 = "/soc/aobus@ff800000/i2c@5000";
		i2c1 = "/soc/cbus@ffd00000/i2c@1e000";
		serial4 = "/soc/aobus@ff800000/serial@4000";
	};

	lcd_extern {
		key_valid = <0x00>;
		status = "okay";
		compatible = "amlogic, lcd_extern";
		i2c_bus = "i2c_bus_0";

		extern_3 {
			init_off = <0x05 0x01 0x28 0xfd 0x01 0x0a 0x05 0x01 0x10 0xfd 0x01 0x96 0xff 0x00>;
			index = <0x03>;
			extern_name = "mipi_default";
			status = "okay";
			init_on = <0x29 0x06 0xf0 0x55 0xaa 0x52 0x08 0x03 0x29 0x0a 0x90 0x03 0x14 0x09 0x00 0x00 0x00 0x38 0x00 0x00 0x29 0x0a 0x91 0x00 0x00 0x00 0x00 0x00 0x00 0x00 0x00 0x00 0x29 0x0c 0x92 0x40 0x0b 0x0c 0x0d 0x0e 0x00 0x38 0x00 0x10 0x03 0x04 0x29 0x09 0x94 0x00 0x08 0x0b 0x03 0xd2 0x03 0xd3 0x0c 0x29 0x11 0x95 0x00 0x00 0x00 0x00 0x00 0x00 0x00 0x00 0x00 0x00 0x00 0x00 0x00 0x00 0x00 0x00 0x29 0x03 0x99 0x00 0x00 0x29 0x0c 0x9a 0x00 0x00 0x00 0x00 0x00 0x00 0x00 0x00 0x00 0x00 0x00 0x29 0x07 0x9b 0x01 0x38 0x00 0x00 0x00 0x00 0x29 0x03 0x9c 0x00 0x00 0x29 0x09 0x9d 0x10 0x10 0x10 0x10 0x10 0x10 0x00 0x00 0x29 0x03 0x9e 0x00 0x00 0x29 0x0b 0xa0 0x9f 0x1f 0x08 0x1f 0x0a 0x1f 0x00 0x1f 0x14 0x1f 0x29 0x0b 0xa1 0x15 0x1f 0x1f 0x1f 0x1f 0x1f 0x1f 0x1f 0x1f 0x1f 0x29 0x0b 0xa2 0x1f 0x1f 0x1f 0x1f 0x1f 0x1f 0x1f 0x1f 0x1f 0x1f 0x29 0x0b 0xa4 0x1f 0x1f 0x1f 0x1f 0x1f 0x1f 0x1f 0x1f 0x1f 0x1f 0x29 0x0b 0xa5 0x1f 0x1f 0x1f 0x1f 0x1f 0x1f 0x1f 0x1f 0x1f 0x15 0x29 0x0b 0xa6 0x1f 0x14 0x1f 0x01 0x1f 0x0b 0x1f 0x09 0x1f 0x1f 0x29 0x0b 0xa7 0x1f 0x1f 0x0b 0x1f 0x09 0x1f 0x01 0x1f 0x15 0x1f 0x29 0x0b 0xa8 0x14 0x1f 0x1f 0x1f 0x1f 0x1f 0x1f 0x1f 0x1f 0x1f 0x29 0x0b 0xa9 0x1f 0x1f 0x1f 0x1f 0x1f 0x1f 0x1f 0x1f 0x1f 0x1f 0x29 0x0b 0xab 0x1f 0x1f 0x1f 0x1f 0x1f 0x1f 0x1f 0x1f 0x1f 0x1f 0x29 0x0b 0xac 0x1f 0x1f 0x1f 0x1f 0x1f 0x1f 0x1f 0x1f 0x1f 0x14 0x29 0x0b 0xad 0x1f 0x15 0x1f 0x00 0x1f 0x08 0x1f 0x0a 0x1f 0x1f 0x29 0x06 0xf0 0x55 0xaa 0x52 0x08 0x00 0x29 0x04 0xbc 0x00 0x00 0x00 0x29 0x05 0xb8 0x01 0xaf 0x8f 0x8f 0x29 0x06 0xf0 0x55 0xaa 0x52 0x08 0x01 0x29 0x11 0xd1 0x00 0x00 0x00 0x09 0x00 0x1f 0x00 0x30 0x00 0x3f 0x00 0x5d 0x00 0x79 0x00 0xa7 0x29 0x11 0xd2 0x00 0xcf 0x01 0x12 0x01 0x49 0x01 0xa1 0x01 0xeb 0x01 0xed 0x02 0x2f 0x02 0x74 0x29 0x11 0xd3 0x02 0x9f 0x02 0xd5 0x02 0xfb 0x03 0x2c 0x03 0x4b 0x03 0x73 0x03 0x8c 0x03 0xa5 0x29 0x05 0xd4 0x03 0xc5 0x03 0xff 0x29 0x11 0xd5 0x00 0x00 0x00 0x09 0x00 0x1f 0x00 0x30 0x00 0x3f 0x00 0x5d 0x00 0x79 0x00 0xa7 0x29 0x11 0xd6 0x00 0xcf 0x01 0x12 0x01 0x49 0x01 0xa1 0x01 0xeb 0x01 0xed 0x02 0x2f 0x02 0x74 0x29 0x11 0xd7 0x02 0x9f 0x02 0xd5 0x02 0xfb 0x03 0x2c 0x03 0x4b 0x03 0x73 0x03 0x8c 0x03 0xa5 0x29 0x05 0xd8 0x03 0xc5 0x03 0xff 0x29 0x11 0xd9 0x00 0x00 0x00 0x09 0x00 0x1f 0x00 0x30 0x00 0x3f 0x00 0x5d 0x00 0x79 0x00 0xa7 0x29 0x11 0xdd 0x00 0xcf 0x01 0x12 0x01 0x49 0x01 0xa1 0x01 0xeb 0x01 0xed 0x02 0x2f 0x02 0x74 0x29 0x11 0xde 0x02 0x9f 0x02 0xd5 0x02 0xfb 0x03 0x2c 0x03 0x4b 0x03 0x73 0x03 0x8c 0x03 0xa5 0x29 0x05 0xdf 0x03 0xc5 0x03 0xff 0x29 0x11 0xe0 0x00 0x00 0x00 0x09 0x00 0x1f 0x00 0x30 0x00 0x3f 0x00 0x5d 0x00 0x79 0x00 0xa7 0x29 0x11 0xe1 0x00 0xcf 0x01 0x12 0x01 0x49 0x01 0xa1 0x01 0xeb 0x01 0xed 0x02 0x2f 0x02 0x74 0x29 0x11 0xe2 0x02 0x9f 0x02 0xd5 0x02 0xfb 0x03 0x2c 0x03 0x4b 0x03 0x73 0x03 0x8c 0x03 0xa5 0x29 0x05 0xe3 0x03 0xc5 0x03 0xff 0x29 0x11 0xe4 0x00 0x00 0x00 0x09 0x00 0x1f 0x00 0x30 0x00 0x3f 0x00 0x5d 0x00 0x79 0x00 0xa7 0x29 0x11 0xe5 0x00 0xcf 0x01 0x12 0x01 0x49 0x01 0xa1 0x01 0xeb 0x01 0xed 0x02 0x2f 0x02 0x74 0x29 0x11 0xe6 0x02 0x9f 0x02 0xd5 0x02 0xfb 0x03 0x2c 0x03 0x4b 0x03 0x73 0x03 0x8c 0x03 0xa5 0x29 0x05 0xe7 0x03 0xc5 0x03 0xff 0x29 0x11 0xe8 0x00 0x00 0x00 0x09 0x00 0x1f 0x00 0x30 0x00 0x3f 0x00 0x5d 0x00 0x79 0x00 0xa7 0x29 0x11 0xe9 0x00 0xcf 0x01 0x12 0x01 0x49 0x01 0xa1 0x01 0xeb 0x01 0xed 0x02 0x2f 0x02 0x74 0x29 0x11 0xea 0x02 0x9f 0x02 0xd5 0x02 0xfb 0x03 0x2c 0x03 0x4b 0x03 0x73 0x03 0x8c 0x03 0xa5 0x29 0x05 0xeb 0x03 0xc5 0x03 0xff 0x29 0x04 0xb0 0x05 0x05 0x05 0x29 0x04 0xb1 0x05 0x05 0x05 0x29 0x04 0xb3 0x10 0x10 0x10 0x29 0x04 0xb4 0x06 0x06 0x06 0x29 0x04 0xb6 0x44 0x44 0x44 0x29 0x04 0xb7 0x34 0x34 0x34 0x29 0x04 0xb8 0x34 0x34 0x34 0x29 0x04 0xb9 0x24 0x24 0x24 0x29 0x04 0xba 0x24 0x24 0x24 0x29 0x04 0xbc 0x00 0x70 0x00 0x29 0x04 0xbd 0x00 0x70 0x00 0x23 0x02 0xbe 0x50 0x23 0x02 0x35 0x00 0x13 0x01 0x11 0xfd 0x01 0xc8 0x13 0x01 0x29 0xfd 0x01 0xc8 0xff 0x00>;
			cmd_size = <0xff>;
			type = <0x02>;
		};

		extern_1 {
			init_off = <0x05 0x01 0x28 0xfd 0x01 0x0a 0x05 0x01 0x10 0xfd 0x01 0x96 0xff 0x00>;
			index = <0x01>;
			extern_name = "mipi_default";
			status = "okay";
			init_on = <0xfd 0x01 0x0a 0x15 0x02 0x62 0x01 0x39 0x05 0xff 0xaa 0x55 0x25 0x01 0x15 0x02 0xfc 0x08 0xfd 0x01 0x01 0x15 0x02 0xfc 0x00 0x39 0x05 0xff 0xaa 0x55 0x25 0x00 0xfd 0x01 0x14 0x39 0x06 0xf0 0x55 0xaa 0x52 0x08 0x00 0x39 0x03 0xb1 0x68 0x41 0x15 0x02 0xb5 0x88 0x15 0x02 0xb6 0x0f 0x39 0x05 0xb8 0x01 0x01 0x12 0x01 0x39 0x03 0xbb 0x11 0x11 0x39 0x03 0xbc 0x05 0x05 0x15 0x02 0xc7 0x03 0x39 0x06 0xbd 0x03 0x02 0x19 0x17 0x00 0x15 0x02 0xc8 0x80 0x39 0x06 0xf0 0x55 0xaa 0x52 0x08 0x01 0x39 0x03 0xb2 0x01 0x01 0x39 0x03 0xb3 0x28 0x28 0x39 0x03 0xb4 0x14 0x14 0x39 0x03 0xb8 0x05 0x05 0x39 0x03 0xb9 0x45 0x45 0x39 0x03 0xba 0x25 0x25 0x39 0x03 0xbc 0x88 0x00 0x39 0x03 0xbd 0x88 0x00 0x39 0x06 0xf0 0x55 0xaa 0x52 0x08 0x02 0x15 0x02 0xee 0x00 0x39 0x11 0xb0 0x00 0x4b 0x00 0x5c 0x00 0x79 0x00 0x94 0x00 0xa6 0x00 0xd8 0x00 0xf2 0x01 0x19 0x39 0x11 0xb1 0x01 0x39 0x01 0x77 0x01 0xa2 0x01 0xf2 0x02 0x32 0x02 0x34 0x02 0x6d 0x02 0xa2 0x39 0x11 0xb2 0x02 0xc7 0x02 0xf2 0x03 0x18 0x03 0x43 0x03 0x65 0x03 0x86 0x03 0x8f 0x03 0x94 0x39 0x05 0xb3 0x03 0x96 0x03 0x98 0x39 0x11 0xb4 0x00 0x84 0x00 0x91 0x00 0xa4 0x00 0xb6 0x00 0xca 0x00 0xe9 0x01 0x02 0x01 0x2a 0x39 0x11 0xb5 0x01 0x49 0x01 0x82 0x01 0xaf 0x01 0xf7 0x02 0x36 0x02 0x38 0x02 0x70 0x02 0xa6 0x39 0x11 0xb6 0x02 0xc8 0x02 0xf5 0x03 0x1a 0x03 0x43 0x03 0x62 0x03 0x82 0x03 0x8f 0x03 0x94 0x39 0x05 0xb7 0x03 0x96 0x03 0x98 0x39 0x11 0xb8 0x01 0x22 0x01 0x27 0x01 0x2e 0x01 0x38 0x01 0x40 0x01 0x53 0x01 0x60 0x01 0x7b 0x39 0x11 0xb9 0x01 0x8c 0x01 0xb5 0x01 0xd3 0x02 0x11 0x02 0x49 0x02 0x4a 0x02 0x7f 0x02 0xb1 0x39 0x11 0xba 0x02 0xd1 0x03 0x00 0x03 0x22 0x03 0x49 0x03 0x60 0x03 0x7a 0x03 0x8b 0x03 0x8f 0x39 0x05 0xbb 0x03 0x93 0x03 0x9a 0x39 0x11 0xbc 0x00 0x37 0x00 0x48 0x00 0x65 0x00 0x80 0x00 0x92 0x00 0xc4 0x00 0xde 0x01 0x05 0x39 0x11 0xbd 0x01 0x31 0x01 0x6f 0x01 0x9e 0x01 0xee 0x02 0x32 0x02 0x34 0x02 0x71 0x02 0xa7 0x39 0x11 0xbe 0x02 0xd3 0x02 0xfe 0x03 0x24 0x03 0x4f 0x03 0x71 0x03 0x92 0x03 0x9b 0x03 0xa0 0x39 0x05 0xbf 0x03 0xa6 0x03 0xa8 0x39 0x11 0xc0 0x00 0x70 0x00 0x7d 0x00 0x90 0x00 0xa4 0x00 0xb6 0x00 0xd5 0x00 0xee 0x01 0x16 0x39 0x11 0xc1 0x01 0x41 0x01 0x7a 0x01 0xab 0x01 0xf3 0x02 0x36 0x02 0x38 0x02 0x74 0x02 0xaa 0x39 0x11 0xc2 0x02 0xd4 0x03 0x01 0x03 0x26 0x03 0x4f 0x03 0x6e 0x03 0x8e 0x03 0x9b 0x03 0xa0 0x39 0x05 0xc3 0x03 0xa6 0x03 0xa8 0x39 0x11 0xc4 0x01 0x0e 0x01 0x13 0x01 0x1a 0x01 0x24 0x01 0x2c 0x01 0x3f 0x01 0x4c 0x01 0x67 0x39 0x11 0xc5 0x01 0x84 0x01 0xad 0x01 0xcf 0x02 0x0d 0x02 0x49 0x02 0x4a 0x02 0x83 0x02 0xb5 0x39 0x11 0xc6 0x02 0xdd 0x03 0x0c 0x03 0x2e 0x03 0x55 0x03 0x6b 0x03 0x86 0x03 0x97 0x03 0x9b 0x39 0x05 0xc7 0x03 0xa1 0x03 0xa8 0x39 0x06 0xf0 0x55 0xaa 0x52 0x08 0x04 0x39 0x06 0xb1 0x03 0x02 0x02 0x02 0x00 0x39 0x06 0xf0 0x55 0xaa 0x52 0x08 0x06 0x39 0x03 0xb0 0x11 0x11 0x39 0x03 0xb1 0x13 0x13 0x39 0x03 0xb2 0x03 0x03 0x39 0x03 0xb3 0x34 0x34 0x39 0x03 0xb4 0x34 0x34 0x39 0x03 0xb5 0x34 0x34 0x39 0x03 0xb6 0x34 0x34 0x39 0x03 0xb7 0x34 0x34 0x39 0x03 0xb8 0x34 0x34 0x39 0x03 0xb9 0x34 0x34 0x39 0x03 0xba 0x34 0x34 0x39 0x03 0xbb 0x34 0x34 0x39 0x03 0xbc 0x34 0x34 0x39 0x03 0xbd 0x34 0x34 0x39 0x03 0xbe 0x34 0x34 0x39 0x03 0xbf 0x34 0x34 0x39 0x03 0xc0 0x34 0x34 0x39 0x03 0xc1 0x02 0x02 0x39 0x03 0xc2 0x12 0x12 0x39 0x03 0xc3 0x10 0x10 0x39 0x03 0xe5 0x34 0x34 0x39 0x06 0xd8 0x00 0x00 0x00 0x00 0x00 0x39 0x06 0xd9 0x00 0x00 0x00 0x00 0x00 0x39 0x06 0xf0 0x55 0xaa 0x52 0x08 0x05 0x15 0x02 0xc0 0x03 0x15 0x02 0xc1 0x02 0x39 0x03 0xc8 0x01 0x20 0x15 0x02 0xe5 0x03 0x15 0x02 0xe6 0x03 0x15 0x02 0xe7 0x03 0x15 0x02 0xe8 0x03 0x15 0x02 0xe9 0x03 0x39 0x05 0xd1 0x03 0x00 0x3d 0x00 0x39 0x06 0xf0 0x55 0xaa 0x52 0x08 0x03 0x39 0x03 0xb0 0x11 0x00 0x39 0x03 0xb1 0x11 0x00 0x39 0x06 0xb2 0x03 0x00 0x00 0x00 0x00 0x39 0x06 0xb3 0x03 0x00 0x00 0x00 0x00 0x39 0x06 0xba 0x31 0x00 0x00 0x00 0x00 0x15 0x02 0x35 0x00 0x15 0x02 0x51 0xff 0x15 0x02 0x53 0x2c 0x15 0x02 0x55 0x03 0x05 0x01 0x11 0xfd 0x01 0x78 0x05 0x01 0x29 0xfd 0x01 0x82 0xff 0x00>;
			cmd_size = <0xff>;
			type = <0x02>;
		};

		extern_7 {
			init_off = <0x05 0x01 0x28 0xfd 0x01 0x0a 0x05 0x01 0x10 0xfd 0x01 0x1e 0xff 0xff>;
			index = <0x07>;
			extern_name = "mipi_ST7701";
			status = "okay";
			init_on = <0x39 0x06 0xff 0x77 0x01 0x00 0x00 0x13 0x39 0x02 0xef 0x08 0x39 0x06 0xff 0x77 0x01 0x00 0x00 0x10 0x39 0x03 0xc0 0x63 0x00 0x39 0x03 0xc1 0x0a 0x02 0x39 0x03 0xc2 0x31 0x07 0x39 0x02 0xcc 0x10 0x39 0x11 0xb0 0x0a 0x10 0x96 0x0e 0x11 0x06 0x06 0x0a 0x08 0x24 0x07 0x53 0x11 0x68 0xad 0xd1 0x39 0x11 0xb1 0x06 0x8d 0xd3 0x09 0x0d 0x04 0x04 0x07 0x07 0x23 0x05 0x15 0x14 0xa7 0xac 0x4f 0x39 0x06 0xff 0x77 0x01 0x00 0x00 0x11 0x39 0x02 0xb0 0x5d 0x39 0x02 0xb1 0x45 0x39 0x02 0xb2 0x82 0x39 0x02 0xb3 0x80 0x39 0x02 0xb5 0x45 0x39 0x02 0xb7 0x85 0x39 0x02 0xb8 0x21 0x39 0x03 0xb9 0x10 0x1f 0x39 0x02 0xbb 0x03 0x39 0x02 0xbc 0x3e 0x39 0x02 0xc1 0x78 0x39 0x02 0xc2 0x78 0x39 0x02 0xd0 0x88 0xfd 0x01 0x08 0x39 0x04 0xe0 0x00 0x00 0x02 0x39 0x0c 0xe1 0x04 0x00 0x00 0x00 0x05 0x00 0x00 0x00 0x00 0x20 0x20 0x39 0x0d 0xe2 0x00 0x00 0x00 0x00 0x00 0x00 0x00 0x00 0x00 0x00 0x00 0x00 0x39 0x05 0xe3 0x00 0x00 0x33 0x00 0x39 0x03 0xe4 0x22 0x00 0x39 0x11 0xe5 0x04 0x34 0x9a 0xa0 0x06 0x34 0x9a 0xa0 0x00 0x00 0x00 0x00 0x00 0x00 0x00 0x00 0x39 0x05 0xe6 0x00 0x00 0x33 0x00 0x39 0x03 0xe7 0x22 0x00 0x39 0x11 0xe8 0x05 0x34 0x9a 0xa0 0x07 0x34 0x9a 0xa0 0x00 0x00 0x00 0x00 0x00 0x00 0x00 0x00 0x39 0x08 0xeb 0x02 0x00 0x40 0x40 0x00 0x00 0x00 0x39 0x03 0xec 0x00 0x00 0x39 0x11 0xed 0xfa 0x45 0x0b 0xff 0xff 0xff 0xff 0xff 0xff 0xff 0xff 0xff 0xff 0xb0 0x54 0xaf 0x39 0x07 0xef 0x08 0x08 0x08 0x45 0x3f 0x54 0x39 0x06 0xff 0x77 0x01 0x00 0x00 0x13 0x39 0x03 0xe8 0x00 0x0e 0x39 0x06 0xff 0x77 0x01 0x00 0x00 0x00 0x39 0x02 0x11 0x00 0xfd 0x01 0x78 0x39 0x06 0xff 0x77 0x01 0x00 0x00 0x13 0x39 0x03 0xe8 0x00 0x0c 0xfd 0x01 0x02 0x39 0x03 0xe8 0x00 0x00 0x39 0x06 0xff 0x77 0x01 0x00 0x00 0x00 0x39 0x02 0x35 0x00 0x39 0x02 0x29 0x00 0xfd 0x01 0x0f 0xff 0xff>;
			cmd_size = <0xff>;
			type = <0x02>;
		};

		extern_5 {
			init_off = <0x05 0x01 0x28 0xfd 0x01 0x0a 0x05 0x01 0x10 0xfd 0x01 0x96 0xff 0x00>;
			index = <0x05>;
			extern_name = "mipi_default";
			status = "okay";
			init_on = <0x23 0x02 0xe0 0x00 0x23 0x02 0xe1 0x93 0x23 0x02 0xe2 0x65 0x23 0x02 0xe3 0xf8 0x23 0x02 0x80 0x03 0x23 0x02 0xe0 0x01 0x23 0x02 0x0c 0x74 0x23 0x02 0x17 0x00 0x23 0x02 0x18 0xef 0x23 0x02 0x19 0x00 0x23 0x02 0x1a 0x00 0x23 0x02 0x1b 0xef 0x23 0x02 0x1c 0x00 0x23 0x02 0x1f 0x70 0x23 0x02 0x20 0x2d 0x23 0x02 0x21 0x2d 0x23 0x02 0x22 0x7e 0x23 0x02 0x26 0xf3 0x23 0x02 0x37 0x09 0x23 0x02 0x38 0x04 0x23 0x02 0x39 0x00 0x23 0x02 0x3a 0x01 0x23 0x02 0x3c 0x90 0x23 0x02 0x3d 0xff 0x23 0x02 0x3e 0xff 0x23 0x02 0x3f 0xff 0x23 0x02 0x40 0x02 0x23 0x02 0x41 0x80 0x23 0x02 0x42 0x99 0x23 0x02 0x43 0x14 0x23 0x02 0x44 0x19 0x23 0x02 0x45 0x5a 0x23 0x02 0x4b 0x04 0x23 0x02 0x55 0x02 0x23 0x02 0x56 0x01 0x23 0x02 0x57 0x69 0x23 0x02 0x58 0x0a 0x23 0x02 0x59 0x0a 0x23 0x02 0x5a 0x2e 0x23 0x02 0x5b 0x19 0x23 0x02 0x5c 0x15 0x23 0x02 0x5d 0x77 0x23 0x02 0x5e 0x56 0x23 0x02 0x5f 0x45 0x23 0x02 0x60 0x38 0x23 0x02 0x61 0x35 0x23 0x02 0x62 0x27 0x23 0x02 0x63 0x2d 0x23 0x02 0x64 0x18 0x23 0x02 0x65 0x33 0x23 0x02 0x66 0x34 0x23 0x02 0x67 0x35 0x23 0x02 0x68 0x56 0x23 0x02 0x69 0x45 0x23 0x02 0x6a 0x4f 0x23 0x02 0x6b 0x42 0x23 0x02 0x6c 0x40 0x23 0x02 0x6d 0x34 0x23 0x02 0x6e 0x25 0x23 0x02 0x6f 0x02 0x23 0x02 0x70 0x77 0x23 0x02 0x71 0x56 0x23 0x02 0x72 0x45 0x23 0x02 0x73 0x38 0x23 0x02 0x74 0x35 0x23 0x02 0x75 0x27 0x23 0x02 0x76 0x2d 0x23 0x02 0x77 0x18 0x23 0x02 0x78 0x33 0x23 0x02 0x79 0x34 0x23 0x02 0x7a 0x35 0x23 0x02 0x7b 0x56 0x23 0x02 0x7c 0x45 0x23 0x02 0x7d 0x4f 0x23 0x02 0x7e 0x42 0x23 0x02 0x7f 0x40 0x23 0x02 0x80 0x34 0x23 0x02 0x81 0x25 0x23 0x02 0x82 0x02 0x23 0x02 0xe0 0x02 0x23 0x02 0x00 0x53 0x23 0x02 0x01 0x55 0x23 0x02 0x02 0x55 0x23 0x02 0x03 0x51 0x23 0x02 0x04 0x77 0x23 0x02 0x05 0x57 0x23 0x02 0x06 0x1f 0x23 0x02 0x07 0x4f 0x23 0x02 0x08 0x4d 0x23 0x02 0x09 0x1f 0x23 0x02 0x0a 0x4b 0x23 0x02 0x0b 0x49 0x23 0x02 0x0c 0x1f 0x23 0x02 0x0d 0x47 0x23 0x02 0x0e 0x45 0x23 0x02 0x0f 0x41 0x23 0x02 0x10 0x1f 0x23 0x02 0x11 0x1f 0x23 0x02 0x12 0x1f 0x23 0x02 0x13 0x55 0x23 0x02 0x14 0x1f 0x23 0x02 0x15 0x1f 0x23 0x02 0x16 0x52 0x23 0x02 0x17 0x55 0x23 0x02 0x18 0x55 0x23 0x02 0x19 0x50 0x23 0x02 0x1a 0x77 0x23 0x02 0x1b 0x57 0x23 0x02 0x1c 0x1f 0x23 0x02 0x1d 0x4e 0x23 0x02 0x1e 0x4c 0x23 0x02 0x1f 0x1f 0x23 0x02 0x20 0x4a 0x23 0x02 0x21 0x48 0x23 0x02 0x22 0x1f 0x23 0x02 0x23 0x46 0x23 0x02 0x24 0x44 0x23 0x02 0x25 0x40 0x23 0x02 0x26 0x1f 0x23 0x02 0x27 0x1f 0x23 0x02 0x28 0x1f 0x23 0x02 0x29 0x1f 0x23 0x02 0x2a 0x1f 0x23 0x02 0x2b 0x55 0x23 0x02 0x2c 0x12 0x23 0x02 0x2d 0x15 0x23 0x02 0x2e 0x15 0x23 0x02 0x2f 0x00 0x23 0x02 0x30 0x37 0x23 0x02 0x31 0x17 0x23 0x02 0x32 0x1f 0x23 0x02 0x33 0x08 0x23 0x02 0x34 0x0a 0x23 0x02 0x35 0x1f 0x23 0x02 0x36 0x0c 0x23 0x02 0x37 0x0e 0x23 0x02 0x38 0x1f 0x23 0x02 0x39 0x04 0x23 0x02 0x3a 0x06 0x23 0x02 0x3b 0x10 0x23 0x02 0x3c 0x1f 0x23 0x02 0x3d 0x1f 0x23 0x02 0x3e 0x1f 0x23 0x02 0x3f 0x15 0x23 0x02 0x40 0x1f 0x23 0x02 0x41 0x1f 0x23 0x02 0x42 0x13 0x23 0x02 0x43 0x15 0x23 0x02 0x44 0x15 0x23 0x02 0x45 0x01 0x23 0x02 0x46 0x37 0x23 0x02 0x47 0x17 0x23 0x02 0x48 0x1f 0x23 0x02 0x49 0x09 0x23 0x02 0x4a 0x0b 0x23 0x02 0x4b 0x1f 0x23 0x02 0x4c 0x0d 0x23 0x02 0x4d 0x0f 0x23 0x02 0x4e 0x1f 0x23 0x02 0x4f 0x05 0x23 0x02 0x50 0x07 0x23 0x02 0x51 0x11 0x23 0x02 0x52 0x1f 0x23 0x02 0x53 0x1f 0x23 0x02 0x54 0x1f 0x23 0x02 0x55 0x1f 0x23 0x02 0x56 0x1f 0x23 0x02 0x57 0x15 0x23 0x02 0x58 0x40 0x23 0x02 0x59 0x00 0x23 0x02 0x5a 0x00 0x23 0x02 0x5b 0x10 0x23 0x02 0x5c 0x14 0x23 0x02 0x5d 0x40 0x23 0x02 0x5e 0x01 0x23 0x02 0x5f 0x02 0x23 0x02 0x60 0x40 0x23 0x02 0x61 0x03 0x23 0x02 0x62 0x04 0x23 0x02 0x63 0x7a 0x23 0x02 0x64 0x7a 0x23 0x02 0x65 0x74 0x23 0x02 0x66 0x16 0x23 0x02 0x67 0xb4 0x23 0x02 0x68 0x16 0x23 0x02 0x69 0x7a 0x23 0x02 0x6a 0x7a 0x23 0x02 0x6b 0x0c 0x23 0x02 0x6c 0x00 0x23 0x02 0x6d 0x04 0x23 0x02 0x6e 0x04 0x23 0x02 0x6f 0x88 0x23 0x02 0x70 0x00 0x23 0x02 0x71 0x00 0x23 0x02 0x72 0x06 0x23 0x02 0x73 0x7b 0x23 0x02 0x74 0x00 0x23 0x02 0x75 0xbc 0x23 0x02 0x76 0x00 0x23 0x02 0x77 0x04 0x23 0x02 0x78 0x2c 0x23 0x02 0x79 0x00 0x23 0x02 0x7a 0x00 0x23 0x02 0x7b 0x00 0x23 0x02 0x7c 0x00 0x23 0x02 0x7d 0x03 0x23 0x02 0x7e 0x7b 0x23 0x02 0xe0 0x04 0x23 0x02 0x09 0x11 0x23 0x02 0x0e 0x48 0x23 0x02 0x2b 0x2b 0x23 0x02 0x2e 0x44 0x23 0x02 0xe0 0x00 0x23 0x02 0xe6 0x02 0x23 0x02 0xe7 0x0c 0x05 0x01 0x11 0xfd 0x01 0x78 0x05 0x01 0x29 0x05 0x01 0x35 0xfd 0x01 0x14 0xff 0x00>;
			cmd_size = <0xff>;
			type = <0x02>;
		};

		extern_4 {
			init_off = <0x05 0x01 0x28 0xfd 0x01 0x0a 0x05 0x01 0x10 0xfd 0x01 0x96 0xff 0x00>;
			index = <0x04>;
			extern_name = "mipi_default";
			status = "okay";
			init_on = <0x23 0x02 0xe0 0x00 0x23 0x02 0xe1 0x93 0x23 0x02 0xe2 0x65 0x23 0x02 0xe3 0xf8 0x23 0x02 0xe0 0x01 0x23 0x02 0x00 0x00 0x23 0x02 0x01 0x90 0x23 0x02 0x03 0x00 0x23 0x02 0x04 0x90 0x23 0x02 0x17 0x00 0x23 0x02 0x18 0xb0 0x23 0x02 0x19 0x01 0x23 0x02 0x1a 0x00 0x23 0x02 0x1b 0xb0 0x23 0x02 0x1c 0x01 0x23 0x02 0x1f 0x3e 0x23 0x02 0x20 0x2f 0x23 0x02 0x21 0x2f 0x23 0x02 0x22 0x0e 0x23 0x02 0x37 0x69 0x23 0x02 0x38 0x05 0x23 0x02 0x39 0x00 0x23 0x02 0x3a 0x01 0x23 0x02 0x3c 0x90 0x23 0x02 0x3d 0xff 0x23 0x02 0x3e 0xff 0x23 0x02 0x3f 0xff 0x23 0x02 0x40 0x02 0x23 0x02 0x41 0x80 0x23 0x02 0x42 0x99 0x23 0x02 0x43 0x06 0x23 0x02 0x44 0x09 0x23 0x02 0x45 0x3c 0x23 0x02 0x4b 0x04 0x23 0x02 0x55 0x0f 0x23 0x02 0x56 0x01 0x23 0x02 0x57 0x89 0x23 0x02 0x58 0x0a 0x23 0x02 0x59 0x0a 0x23 0x02 0x5a 0x27 0x23 0x02 0x5b 0x15 0x23 0x02 0x5d 0x7c 0x23 0x02 0x5e 0x67 0x23 0x02 0x5f 0x58 0x23 0x02 0x60 0x4c 0x23 0x02 0x61 0x48 0x23 0x02 0x62 0x38 0x23 0x02 0x63 0x3c 0x23 0x02 0x64 0x24 0x23 0x02 0x65 0x3b 0x23 0x02 0x66 0x38 0x23 0x02 0x67 0x36 0x23 0x02 0x68 0x53 0x23 0x02 0x69 0x3f 0x23 0x02 0x6a 0x44 0x23 0x02 0x6b 0x35 0x23 0x02 0x6c 0x2e 0x23 0x02 0x6d 0x1f 0x23 0x02 0x6e 0x0c 0x23 0x02 0x6f 0x00 0x23 0x02 0x70 0x7c 0x23 0x02 0x71 0x67 0x23 0x02 0x72 0x58 0x23 0x02 0x73 0x4c 0x23 0x02 0x74 0x48 0x23 0x02 0x75 0x38 0x23 0x02 0x76 0x3c 0x23 0x02 0x77 0x24 0x23 0x02 0x78 0x3b 0x23 0x02 0x79 0x38 0x23 0x02 0x7a 0x36 0x23 0x02 0x7b 0x53 0x23 0x02 0x7c 0x3f 0x23 0x02 0x7d 0x44 0x23 0x02 0x7e 0x35 0x23 0x02 0x7f 0x2e 0x23 0x02 0x80 0x1f 0x23 0x02 0x81 0x0c 0x23 0x02 0x82 0x00 0x23 0x02 0xe0 0x02 0x23 0x02 0x00 0x45 0x23 0x02 0x01 0x45 0x23 0x02 0x02 0x47 0x23 0x02 0x03 0x47 0x23 0x02 0x04 0x41 0x23 0x02 0x05 0x41 0x23 0x02 0x06 0x1f 0x23 0x02 0x07 0x1f 0x23 0x02 0x08 0x1f 0x23 0x02 0x09 0x1f 0x23 0x02 0x0a 0x1f 0x23 0x02 0x0b 0x1f 0x23 0x02 0x0c 0x1f 0x23 0x02 0x0d 0x1d 0x23 0x02 0x0e 0x1d 0x23 0x02 0x0f 0x1d 0x23 0x02 0x10 0x1f 0x23 0x02 0x11 0x1f 0x23 0x02 0x12 0x1f 0x23 0x02 0x13 0x1f 0x23 0x02 0x14 0x1f 0x23 0x02 0x15 0x1f 0x23 0x02 0x16 0x44 0x23 0x02 0x17 0x44 0x23 0x02 0x18 0x46 0x23 0x02 0x19 0x46 0x23 0x02 0x1a 0x40 0x23 0x02 0x1b 0x40 0x23 0x02 0x1c 0x1f 0x23 0x02 0x1d 0x1f 0x23 0x02 0x1e 0x1f 0x23 0x02 0x1f 0x1f 0x23 0x02 0x20 0x1f 0x23 0x02 0x21 0x1f 0x23 0x02 0x22 0x1f 0x23 0x02 0x23 0x1d 0x23 0x02 0x24 0x1d 0x23 0x02 0x25 0x1d 0x23 0x02 0x26 0x1f 0x23 0x02 0x27 0x1f 0x23 0x02 0x28 0x1f 0x23 0x02 0x29 0x1f 0x23 0x02 0x2a 0x1f 0x23 0x02 0x2b 0x1f 0x23 0x02 0x58 0x40 0x23 0x02 0x59 0x00 0x23 0x02 0x5a 0x00 0x23 0x02 0x5b 0x10 0x23 0x02 0x5c 0x06 0x23 0x02 0x5d 0x20 0x23 0x02 0x5e 0x00 0x23 0x02 0x5f 0x00 0x23 0x02 0x61 0x00 0x23 0x02 0x62 0x00 0x23 0x02 0x63 0x7a 0x23 0x02 0x64 0x7a 0x23 0x02 0x65 0x00 0x23 0x02 0x66 0x00 0x23 0x02 0x67 0x32 0x23 0x02 0x68 0x08 0x23 0x02 0x69 0x7a 0x23 0x02 0x6a 0x7a 0x23 0x02 0x6b 0x00 0x23 0x02 0x6c 0x00 0x23 0x02 0x6d 0x04 0x23 0x02 0x6e 0x04 0x23 0x02 0x6f 0x88 0x23 0x02 0x70 0x00 0x23 0x02 0x71 0x00 0x23 0x02 0x72 0x06 0x23 0x02 0x73 0x7b 0x23 0x02 0x74 0x00 0x23 0x02 0x75 0x07 0x23 0x02 0x76 0x00 0x23 0x02 0x77 0x5d 0x23 0x02 0x78 0x17 0x23 0x02 0x79 0x1f 0x23 0x02 0x7a 0x00 0x23 0x02 0x7b 0x00 0x23 0x02 0x7c 0x00 0x23 0x02 0x7d 0x03 0x23 0x02 0x7e 0x7b 0x23 0x02 0xe0 0x03 0x23 0x02 0xaf 0x20 0x23 0x02 0xe0 0x04 0x23 0x02 0x09 0x11 0x23 0x02 0x0e 0x48 0x23 0x02 0x2b 0x2b 0x23 0x02 0x2e 0x44 0x23 0x02 0x41 0xff 0x23 0x02 0xe0 0x00 0x23 0x02 0xe6 0x02 0x23 0x02 0xe7 0x0c 0x05 0x01 0x11 0xfd 0x01 0x78 0x23 0x02 0xe0 0x03 0x23 0x02 0x2b 0x01 0x23 0x02 0x2c 0x00 0x23 0x02 0x30 0x03 0x23 0x02 0x31 0xcc 0x23 0x02 0x32 0x03 0x23 0x02 0x33 0xc9 0x23 0x02 0x34 0x03 0x23 0x02 0x35 0xc0 0x23 0x02 0x36 0x03 0x23 0x02 0x37 0xb3 0x23 0x02 0x38 0x03 0x23 0x02 0x39 0xab 0x23 0x02 0x3a 0x03 0x23 0x02 0x3b 0x9d 0x23 0x02 0x3c 0x03 0x23 0x02 0x3d 0x8f 0x23 0x02 0x3e 0x03 0x23 0x02 0x3f 0x6d 0x23 0x02 0x40 0x03 0x23 0x02 0x41 0x51 0x23 0x02 0x42 0x03 0x23 0x02 0x43 0x17 0x23 0x02 0x44 0x02 0x23 0x02 0x45 0xd8 0x23 0x02 0x46 0x02 0x23 0x02 0x47 0x60 0x23 0x02 0x48 0x01 0x23 0x02 0x49 0xeb 0x23 0x02 0x4a 0x01 0x23 0x02 0x4b 0xe5 0x23 0x02 0x4c 0x01 0x23 0x02 0x4d 0x6c 0x23 0x02 0x4e 0x00 0x23 0x02 0x4f 0xf2 0x23 0x02 0x50 0x00 0x23 0x02 0x51 0xb4 0x23 0x02 0x52 0x00 0x23 0x02 0x53 0x74 0x23 0x02 0x54 0x00 0x23 0x02 0x55 0x54 0x23 0x02 0x56 0x00 0x23 0x02 0x57 0x34 0x23 0x02 0x58 0x00 0x23 0x02 0x59 0x26 0x23 0x02 0x5a 0x00 0x23 0x02 0x5b 0x18 0x23 0x02 0x5c 0x00 0x23 0x02 0x5d 0x11 0x23 0x02 0x5e 0x00 0x23 0x02 0x5f 0x0a 0x23 0x02 0x60 0x00 0x23 0x02 0x61 0x03 0x23 0x02 0x62 0x00 0x23 0x02 0x63 0x00 0x23 0x02 0x64 0x03 0x23 0x02 0x65 0x9e 0x23 0x02 0x66 0x03 0x23 0x02 0x67 0x9b 0x23 0x02 0x68 0x03 0x23 0x02 0x69 0x94 0x23 0x02 0x6a 0x03 0x23 0x02 0x6b 0x8c 0x23 0x02 0x6c 0x03 0x23 0x02 0x6d 0x85 0x23 0x02 0x6e 0x03 0x23 0x02 0x6f 0x76 0x23 0x02 0x70 0x03 0x23 0x02 0x71 0x67 0x23 0x02 0x72 0x03 0x23 0x02 0x73 0x4b 0x23 0x02 0x74 0x03 0x23 0x02 0x75 0x2e 0x23 0x02 0x76 0x02 0x23 0x02 0x77 0xf7 0x23 0x02 0x78 0x02 0x23 0x02 0x79 0xb8 0x23 0x02 0x7a 0x02 0x23 0x02 0x7b 0x46 0x23 0x02 0x7c 0x01 0x23 0x02 0x7d 0xd6 0x23 0x02 0x7e 0x01 0x23 0x02 0x7f 0xd0 0x23 0x02 0x80 0x01 0x23 0x02 0x81 0x5c 0x23 0x02 0x82 0x00 0x23 0x02 0x83 0xe7 0x23 0x02 0x84 0x00 0x23 0x02 0x85 0xaa 0x23 0x02 0x86 0x00 0x23 0x02 0x87 0x74 0x23 0x02 0x88 0x00 0x23 0x02 0x89 0x5a 0x23 0x02 0x8a 0x00 0x23 0x02 0x8b 0x3c 0x23 0x02 0x8c 0x00 0x23 0x02 0x8d 0x2c 0x23 0x02 0x8e 0x00 0x23 0x02 0x8f 0x1c 0x23 0x02 0x90 0x00 0x23 0x02 0x91 0x14 0x23 0x02 0x92 0x00 0x23 0x02 0x93 0x0c 0x23 0x02 0x94 0x00 0x23 0x02 0x95 0x04 0x23 0x02 0x96 0x00 0x23 0x02 0x97 0x00 0x23 0x02 0xe0 0x00 0x05 0x01 0x29 0xfd 0x01 0x05 0xff 0x00>;
			cmd_size = <0xff>;
			type = <0x02>;
		};

		extern_2 {
			init_off = <0x05 0x01 0x28 0xfd 0x01 0x0a 0x05 0x01 0x10 0xfd 0x01 0x96 0xff 0x00>;
			index = <0x02>;
			extern_name = "mipi_default";
			status = "okay";
			init_on = <0x29 0x05 0xff 0xaa 0x55 0x25 0x01 0x23 0x02 0xfc 0x08 0xfd 0x01 0x01 0x23 0x02 0xfc 0x00 0xfd 0x01 0x01 0x23 0x02 0x6f 0x21 0x23 0x02 0xf7 0x01 0xfd 0x01 0x01 0x23 0x02 0x6f 0x21 0x23 0x02 0xf7 0x00 0xfd 0x01 0x01 0x23 0x02 0x6f 0x1a 0x23 0x02 0xf7 0x05 0xfd 0x01 0x01 0x29 0x05 0xff 0xaa 0x55 0x25 0x00 0x29 0x06 0xf0 0x55 0xaa 0x52 0x08 0x00 0x29 0x03 0xb1 0x68 0x41 0x23 0x02 0xb5 0x88 0x29 0x06 0xbd 0x02 0xb0 0x0c 0x14 0x00 0x23 0x02 0xc8 0x80 0x29 0x06 0xf0 0x55 0xaa 0x52 0x08 0x01 0x29 0x03 0xb3 0x2d 0x2d 0x29 0x03 0xb4 0x19 0x19 0x23 0x02 0xb5 0x06 0x29 0x03 0xb9 0x36 0x36 0x29 0x03 0xba 0x26 0x26 0x29 0x03 0xbc 0xa8 0x01 0x29 0x03 0xbd 0xab 0x01 0x23 0x02 0xc0 0x0c 0x29 0x06 0xf0 0x55 0xaa 0x52 0x08 0x02 0x23 0x02 0xee 0x02 0x29 0x07 0xb0 0x00 0x50 0x00 0x52 0x00 0x73 0x23 0x02 0x6f 0x06 0x29 0x07 0xb0 0x00 0x8f 0x00 0xa5 0x00 0xca 0x23 0x02 0x6f 0x0c 0x29 0x05 0xb0 0x00 0xea 0x01 0x1b 0x29 0x07 0xb1 0x01 0x42 0x01 0x82 0x01 0xb3 0x23 0x02 0x6f 0x06 0x29 0x07 0xb1 0x02 0x00 0x02 0x41 0x02 0x42 0x23 0x02 0x6f 0x0c 0x29 0x05 0xb1 0x02 0x78 0x02 0xb5 0x29 0x07 0xb2 0x02 0xda 0x03 0x12 0x03 0x3a 0x23 0x02 0x6f 0x06 0x29 0x07 0xb2 0x03 0x6e 0x03 0x8d 0x03 0xb1 0x23 0x02 0x6f 0x0c 0x29 0x05 0xb2 0x03 0xca 0x03 0xe8 0x29 0x05 0xb3 0x03 0xf4 0x03 0xff 0x29 0x07 0xbc 0x00 0x05 0x00 0x52 0x00 0x73 0x23 0x02 0x6f 0x06 0x29 0x07 0xbc 0x00 0x8f 0x00 0xa5 0x00 0xca 0x23 0x02 0x6f 0x0c 0x29 0x05 0xbc 0x00 0xea 0x01 0x1b 0x29 0x07 0xbd 0x01 0x42 0x01 0x82 0x01 0xb3 0x23 0x02 0x6f 0x06 0x29 0x07 0xbd 0x02 0x00 0x02 0x41 0x02 0x42 0x23 0x02 0x6f 0x0c 0x29 0x05 0xbd 0x02 0x78 0x02 0xb5 0x29 0x07 0xbe 0x02 0xda 0x03 0x12 0x03 0x3a 0x23 0x02 0x6f 0x06 0x29 0x07 0xbe 0x03 0x6e 0x03 0x8d 0x03 0xb1 0x23 0x02 0x6f 0x0c 0x29 0x05 0xbe 0x03 0xca 0x03 0xe8 0x29 0x05 0xbf 0x03 0xf4 0x03 0xff 0x29 0x06 0xf0 0x55 0xaa 0x52 0x08 0x03 0x29 0x06 0xb2 0x05 0x00 0x00 0x00 0x00 0x29 0x06 0xb6 0x05 0x00 0x00 0x00 0x00 0x29 0x06 0xb7 0x05 0x00 0x00 0x00 0x00 0x29 0x06 0xba 0x57 0x00 0x00 0x00 0x00 0x29 0x06 0xbb 0x57 0x00 0x00 0x00 0x00 0x29 0x05 0xc0 0x00 0x34 0x00 0x00 0x29 0x05 0xc1 0x00 0x00 0x34 0x00 0x23 0x02 0xc4 0x40 0x29 0x06 0xf0 0x55 0xaa 0x52 0x08 0x05 0x29 0x03 0xb0 0x17 0x06 0x29 0x03 0xb1 0x17 0x06 0x29 0x03 0xb2 0x17 0x06 0x29 0x03 0xb3 0x17 0x06 0x29 0x03 0xb4 0x17 0x06 0x29 0x06 0xbd 0x03 0x01 0x03 0x03 0x01 0x23 0x02 0xc0 0x05 0x23 0x02 0xc4 0x82 0x23 0x02 0xc5 0xa2 0x29 0x03 0xc8 0x03 0x30 0x29 0x03 0xc9 0x03 0x31 0x29 0x04 0xcc 0x00 0x00 0x3c 0x29 0x04 0xcd 0x00 0x00 0x3c 0x29 0x06 0xd1 0x00 0x44 0x09 0x00 0x00 0x29 0x06 0xd2 0x00 0x04 0x0b 0x00 0x00 0x29 0x06 0xf0 0x55 0xaa 0x52 0x08 0x06 0x29 0x03 0xb0 0x0b 0x2d 0x29 0x03 0xb1 0x2d 0x09 0x29 0x03 0xb2 0x2a 0x29 0x29 0x03 0xb3 0x34 0x1b 0x29 0x03 0xb4 0x19 0x17 0x29 0x03 0xb5 0x15 0x13 0x29 0x03 0xb6 0x11 0x01 0x29 0x03 0xb7 0x34 0x34 0x29 0x03 0xb8 0x34 0x2d 0x29 0x03 0xb9 0x2d 0x34 0x29 0x03 0xba 0x2d 0x2d 0x29 0x03 0xbb 0x34 0x34 0x29 0x03 0xbc 0x34 0x34 0x29 0x03 0xbd 0x00 0x10 0x29 0x03 0xbe 0x12 0x14 0x29 0x03 0xbf 0x16 0x18 0x29 0x03 0xc0 0x1a 0x34 0x29 0x03 0xc1 0x29 0x2a 0x29 0x03 0xc2 0x08 0x2d 0x29 0x03 0xc3 0x2d 0x0a 0x29 0x03 0xc4 0x0a 0x2d 0x29 0x03 0xc5 0x2d 0x00 0x29 0x03 0xc6 0x2a 0x29 0x29 0x03 0xc7 0x34 0x14 0x29 0x03 0xc8 0x16 0x18 0x29 0x03 0xc9 0x1a 0x10 0x29 0x03 0xca 0x12 0x08 0x29 0x03 0xcb 0x34 0x34 0x29 0x03 0xcc 0x34 0x2d 0x29 0x03 0xcd 0x2d 0x34 0x29 0x03 0xce 0x2d 0x2d 0x29 0x03 0xcf 0x34 0x34 0x29 0x03 0xd0 0x34 0x34 0x29 0x03 0xd1 0x09 0x13 0x29 0x03 0xd2 0x11 0x1b 0x29 0x03 0xd3 0x19 0x17 0x29 0x03 0xd4 0x15 0x34 0x29 0x03 0xd5 0x29 0x2a 0x29 0x03 0xd6 0x01 0x2d 0x29 0x03 0xd7 0x2d 0x0b 0x29 0x06 0xd8 0x00 0x00 0x00 0x00 0x00 0x29 0x06 0xd9 0x00 0x00 0x00 0x00 0x00 0x29 0x03 0xe5 0x34 0x34 0x29 0x03 0xe6 0x34 0x34 0x23 0x02 0xe7 0x00 0x29 0x03 0xe8 0x34 0x34 0x29 0x03 0xe9 0x34 0x34 0x23 0x02 0xea 0x00 0x29 0x06 0xf0 0x55 0xaa 0x52 0x00 0x00 0x13 0x01 0x35 0x13 0x01 0x11 0xfd 0x01 0x78 0x13 0x01 0x29 0xfd 0x01 0x14 0xff 0x00>;
			cmd_size = <0xff>;
			type = <0x02>;
		};

		extern_6 {
			init_off = <0x05 0x01 0x28 0xfd 0x01 0x0a 0x05 0x01 0x10 0xfd 0x01 0x1e 0xff 0xff>;
			index = <0x06>;
			extern_name = "mipi_ILI9806E";
			status = "okay";
			init_on = <0x39 0x06 0xff 0xff 0x98 0x06 0x04 0x01 0x15 0x02 0x08 0x10 0x15 0x02 0x20 0x00 0x15 0x02 0x21 0x01 0x15 0x02 0x30 0x02 0x15 0x02 0x31 0x02 0x15 0x02 0x60 0x07 0x15 0x02 0x61 0x06 0x15 0x02 0x62 0x06 0x15 0x02 0x63 0x04 0x15 0x02 0x40 0x18 0x15 0x02 0x41 0x33 0x15 0x02 0x42 0x12 0x15 0x02 0x43 0x89 0x15 0x02 0x44 0x86 0x15 0x02 0x46 0x55 0x15 0x02 0x47 0x55 0x15 0x02 0x45 0x14 0x15 0x02 0x50 0x50 0x15 0x02 0x51 0x50 0x15 0x02 0x52 0x00 0x15 0x02 0x53 0x38 0x15 0x02 0xa0 0x00 0x15 0x02 0xa1 0x09 0x15 0x02 0xa2 0x0c 0x15 0x02 0xa3 0x0f 0x15 0x02 0xa4 0x06 0x15 0x02 0xa5 0x09 0x15 0x02 0xa6 0x07 0x15 0x02 0xa7 0x16 0x15 0x02 0xa8 0x06 0x15 0x02 0xa9 0x09 0x15 0x02 0xaa 0x11 0x15 0x02 0xab 0x06 0x15 0x02 0xac 0x0e 0x15 0x02 0xad 0x19 0x15 0x02 0xae 0x0e 0x15 0x02 0xaf 0x00 0x15 0x02 0xc0 0x00 0x15 0x02 0xc1 0x09 0x15 0x02 0xc2 0x0c 0x15 0x02 0xc3 0x0f 0x15 0x02 0xc4 0x06 0x15 0x02 0xc5 0x09 0x15 0x02 0xc6 0x07 0x15 0x02 0xc7 0x16 0x15 0x02 0xc8 0x06 0x15 0x02 0xc9 0x09 0x15 0x02 0xca 0x11 0x15 0x02 0xcb 0x06 0x15 0x02 0xcc 0x0e 0x15 0x02 0xcd 0x19 0x15 0x02 0xce 0x0e 0x15 0x02 0xcf 0x00 0x39 0x06 0xff 0xff 0x98 0x06 0x04 0x06 0x15 0x02 0x00 0xa0 0x15 0x02 0x01 0x05 0x15 0x02 0x02 0x00 0x15 0x02 0x03 0x00 0x15 0x02 0x04 0x01 0x15 0x02 0x05 0x01 0x15 0x02 0x06 0x88 0x15 0x02 0x07 0x04 0x15 0x02 0x08 0x01 0x15 0x02 0x09 0x90 0x15 0x02 0x0a 0x04 0x15 0x02 0x0b 0x01 0x15 0x02 0x0c 0x01 0x15 0x02 0x0d 0x01 0x15 0x02 0x0e 0x00 0x15 0x02 0x0f 0x00 0x15 0x02 0x10 0x55 0x15 0x02 0x11 0x50 0x15 0x02 0x12 0x01 0x15 0x02 0x13 0x85 0x15 0x02 0x14 0x85 0x15 0x02 0x15 0xc0 0x15 0x02 0x16 0x0b 0x15 0x02 0x17 0x00 0x15 0x02 0x18 0x00 0x15 0x02 0x19 0x00 0x15 0x02 0x1a 0x00 0x15 0x02 0x1b 0x00 0x15 0x02 0x1c 0x00 0x15 0x02 0x1d 0x00 0x15 0x02 0x20 0x01 0x15 0x02 0x21 0x23 0x15 0x02 0x22 0x45 0x15 0x02 0x23 0x67 0x15 0x02 0x24 0x01 0x15 0x02 0x25 0x23 0x15 0x02 0x26 0x45 0x15 0x02 0x27 0x67 0x15 0x02 0x30 0x02 0x15 0x02 0x31 0x22 0x15 0x02 0x32 0x11 0x15 0x02 0x33 0xaa 0x15 0x02 0x34 0xbb 0x15 0x02 0x35 0x66 0x15 0x02 0x36 0x00 0x15 0x02 0x37 0x22 0x15 0x02 0x38 0x22 0x15 0x02 0x39 0x22 0x15 0x02 0x3a 0x22 0x15 0x02 0x3b 0x22 0x15 0x02 0x3c 0x22 0x15 0x02 0x3d 0x22 0x15 0x02 0x3e 0x22 0x15 0x02 0x3f 0x22 0x15 0x02 0x40 0x22 0x15 0x02 0x52 0x12 0x15 0x02 0x53 0x12 0x39 0x06 0xff 0xff 0x98 0x06 0x04 0x07 0x15 0x02 0x17 0x32 0x15 0x02 0x02 0x17 0x15 0x02 0x18 0x1d 0x15 0x02 0xe1 0x79 0x39 0x06 0xff 0xff 0x98 0x06 0x04 0x00 0x15 0x02 0x3a 0x70 0x05 0x01 0x11 0xfd 0x01 0x78 0x05 0x01 0x29 0xfd 0x01 0x19 0xff 0xff>;
			cmd_size = <0xff>;
			type = <0x02>;
		};

		extern_0 {
			init_off = <0x05 0x01 0x28 0xfd 0x01 0x0a 0x05 0x01 0x10 0xfd 0x01 0x96 0xff 0x00>;
			index = <0x00>;
			extern_name = "mipi_default";
			status = "okay";
			init_on = <0xfd 0x01 0x0a 0x05 0x01 0x11 0xfd 0x01 0x78 0x05 0x01 0x29 0xff 0x00>;
			cmd_size = <0xff>;
			type = <0x02>;
		};
	};

	pinctrl@ff800014 {
		#address-cells = <0x02>;
		compatible = "amlogic,meson-g12a-aobus-pinctrl";
		ranges;
		#size-cells = <0x02>;
		phandle = <0x7b>;

		pwm_ao_b {
			phandle = <0x82>;

			mux {
				function = "pwm_ao_b";
				groups = "pwm_ao_b";
			};
		};

		ao_uart {
			phandle = <0x1f>;

			mux {
				function = "uart_ao_a";
				groups = "uart_ao_tx_a", "uart_ao_rx_a";
			};
		};

		ao_ceca {
			phandle = <0x88>;

			mux {
				function = "cec_ao";
				groups = "cec_ao_a";
			};
		};

		remote_pin {
			phandle = <0x8a>;

			mux {
				function = "remote_input_ao";
				groups = "remote_input_ao";
			};
		};

		pwm_ao_a {
			phandle = <0x80>;

			mux {
				function = "pwm_ao_a";
				groups = "pwm_ao_a";
			};
		};

		pwm_ao_a_hiz {
			phandle = <0x81>;

			mux {
				function = "pwm_ao_a";
				groups = "pwm_ao_a_hiz";
			};
		};

		ao_i2c_pins1 {
			phandle = <0x7e>;

			mux {
				function = "i2c_ao";
				drive-strength = <0x02>;
				groups = "i2c_ao_sck", "i2c_ao_sda";
			};
		};

		irblaster_pin {
			phandle = <0x21>;

			mux {
				function = "remote_out_ao";
				groups = "remote_out_ao";
			};
		};

		pwm_ao_d_pins1 {
			phandle = <0x86>;

			mux {
				function = "pwm_ao_d";
				groups = "pwm_ao_d_5";
			};
		};

		sd_to_ao_uart_clr_pins {
			phandle = <0x7c>;

			mux {
				function = "gpio_aobus";
				groups = "GPIOAO_0", "GPIOAO_1";
			};
		};

		ao_cecb {
			phandle = <0x89>;

			mux {
				function = "cec_ao";
				groups = "cec_ao_b";
			};
		};

		spdifout_a_mute {
			phandle = <0x8c>;

			mux {
				function = "gpio_aobus";
				groups = "GPIOAO_10";
			};
		};

		pwm_ao_c_pins1 {
			phandle = <0x83>;

			mux {
				function = "pwm_ao_c";
				groups = "pwm_ao_c_4";
			};
		};

		pwm_ao_c_pins2 {
			phandle = <0x84>;

			mux {
				function = "pwm_ao_c";
				groups = "pwm_ao_c_6";
			};
		};

		pwm_ao_d_pins3 {
			phandle = <0x72>;

			mux {
				function = "pwm_ao_d";
				groups = "pwm_ao_d_e";
			};
		};

		ao-bank@ff800014 {
			#gpio-cells = <0x02>;
			reg = <0x00 0xff800014 0x00 0x08 0x00 0xff800024 0x00 0x14 0x00 0xff80001c 0x00 0x08>;
			gpio-controller;
			reg-names = "mux", "gpio", "drive-strength";
			phandle = <0x4a>;
		};

		pwm_ao_c_hiz {
			phandle = <0x85>;

			mux {
				function = "pwm_ao_c";
				groups = "pwm_ao_c_hiz_4";
			};
		};

		pwm_ao_d_pins2 {
			phandle = <0x87>;

			mux {
				function = "pwm_ao_d";
				groups = "pwm_ao_d_10";
			};
		};

		sd_to_ao_uart_pins {
			phandle = <0x7d>;

			mux {
				function = "uart_ao_a";
				input-enable;
				groups = "uart_ao_tx_a", "uart_ao_rx_a";
				bias-pull-up;
			};
		};

		jtag_apao_pin {
			phandle = <0x17>;

			mux {
				function = "jtag_a";
				groups = "jtag_a_tdi", "jtag_a_tdo", "jtag_a_clk", "jtag_a_tms";
			};
		};

		ao_i2c_pins2 {
			phandle = <0x7f>;

			mux {
				function = "i2c_ao";
				drive-strength = <0x02>;
				groups = "i2c_ao_sck_e", "i2c_ao_sda_e";
			};
		};

		ao_i2c_slave_pins {
			phandle = <0x1e>;

			mux {
				function = "i2c_ao_slave";
				groups = "i2c_ao_slave_sck", "i2c_ao_slave_sda";
			};
		};

		spdifout {
			phandle = <0x8b>;

			mux {
				function = "spdif_out_ao";
				groups = "spdif_out_ao";
			};
		};

		ao_b_uart {
			phandle = <0x20>;

			mux {
				function = "uart_ao_b";
				groups = "uart_ao_tx_b_2", "uart_ao_rx_b_3";
			};
		};
	};

	ddr_bandwidth {
		status = "okay";
		compatible = "amlogic, ddr-bandwidth";
		reg = <0x00 0xff638000 0x00 0x100 0x00 0xff638c00 0x00 0x100>;
		interrupt-names = "ddr_bandwidth";
		interrupts = <0x00 0x34 0x01>;
	};

	hevc_enc {
		dev_name = "HevcEnc";
		#address-cells = <0x02>;
		status = "okay";
		compatible = "cnm, HevcEnc";
		ranges;
		#size-cells = <0x02>;
		interrupt-names = "wave420l_irq";
		interrupts = <0x00 0xbb 0x01>;

		io_reg_base {
			reg = <0x00 0xff610000 0x00 0x4000>;
		};
	};

	timer {
		compatible = "arm,armv8-timer";
		interrupts = <0x01 0x0d 0xff08 0x01 0x0e 0xff08 0x01 0x0b 0xff08 0x01 0x0a 0xff08>;
	};

	d_tsensor@ff800228 {
		cal_type = <0x01>;
		clock-names = "ts_comp";
		cal_d = <0x24c3>;
		rtemp = <0x1c138>;
		cal_c = <0xc57>;
		status = "okay";
		compatible = "amlogic, r1p1-tsensor";
		cal_b = <0x1a8>;
		#thermal-sensor-cells = <0x01>;
		cal_a = <0x144>;
		reg = <0x00 0xff634c00 0x00 0x50 0x00 0xff800230 0x00 0x04>;
		clocks = <0x02 0xd6>;
		device_name = "meson-dthermal";
		interrupts = <0x00 0x24 0x00>;
		phandle = <0x34>;
	};

	thermal-sensor@0 {
		io-channels = <0x50 0x00>;
		temperature-lookup-table = <0x14c08 0x37e 0x13880 0x36e 0x124f8 0x35c 0x11170 0x347 0xfde8 0x32f 0xea60 0x315 0xd6d8 0x2f7 0xc350 0x2d6 0xafc8 0x2b2 0x9c40 0x28a 0x88b8 0x25f 0x7530 0x230 0x61a8 0x200 0x4e20 0x1ce 0x3a98 0x19b 0x2710 0x168 0x1388 0x137 0x00 0x109 0xffffec78 0xdd 0xffffd8f0 0xb6 0xffffc568 0x93 0xffffb1e0 0x75 0xffff9e58 0x5c 0xffff8ad0 0x46 0xffff7748 0x35 0xffff63c0 0x28>;
		compatible = "generic-adc-thermal";
		#thermal-sensor-cells = <0x00>;
		io-channel-names = "sensor-channel";
		phandle = <0x37>;
	};

	cpu_iomap {
		#address-cells = <0x02>;
		compatible = "amlogic, iomap";
		ranges;
		#size-cells = <0x02>;

		io_hiu_base {
			reg = <0x00 0xff63c000 0x00 0x2000>;
		};

		io_apb_base {
			reg = <0x00 0xffe01000 0x00 0x7f000>;
		};

		io_cbus_base {
			reg = <0x00 0xffd00000 0x00 0x26000>;
		};

		io_aobus_base {
			reg = <0x00 0xff800000 0x00 0xb000>;
		};

		io_vapb_base {
			reg = <0x00 0xff900000 0x00 0x50000>;
		};
	};

	locker {
		dividor = <0x31>;
		clock-names = "lock_out", "lock_in", "out_src", "in_src", "out_calc", "in_ref";
		status = "okay";
		compatible = "amlogic, audiolocker";
		frequency = <0x2ebae40>;
		clocks = <0x23 0x22 0x23 0x23 0x23 0x1a 0x23 0x1b 0x02 0x0d 0x02 0x0e>;
		interrupt-names = "irq";
		interrupts = <0x00 0x01 0x01>;
		phandle = <0x102>;
	};

	rtc {
		status = "okay";
		compatible = "amlogic, aml_vrtc";
		timer_e_addr = <0xffd0f188>;
		alarm_reg_addr = <0xff8000a8>;
		init_date = "2015/01/01";
	};

	rdma {
		dev_name = "amlogic-rdma";
		status = "okay";
		compatible = "amlogic, meson, rdma";
		interrupt-names = "rdma";
		interrupts = <0x00 0x59 0x01>;
	};

	serial@ffd23000 {
		pinctrl-0 = <0x28>;
		clock-names = "clk_uart", "clk_gate";
		fifosize = <0x40>;
		pinctrl-names = "default";
		status = "disabled";
		compatible = "amlogic, meson-uart";
		reg = <0x00 0xffd23000 0x00 0x18>;
		clocks = <0x16 0x02 0x3c>;
		interrupts = <0x00 0x4b 0x01>;
		phandle = <0xe2>;
	};

	drm-amhdmitx {
		dev_name = "meson-amhdmitx";
		status = "disabled";
		compatible = "amlogic,drm-amhdmitx";
		hdcp = "disabled";
		interrupts = <0x00 0x03 0x01>;
		phandle = <0x10a>;

		ports {

			port {
				#address-cells = <0x01>;
				#size-cells = <0x00>;

				endpoint@0 {
					remote-endpoint = <0x104>;
					reg = <0x00>;
					phandle = <0x106>;
				};
			};
		};
	};

	drm-subsystem {
		ports = <0x108>;
		status = "okay";
		compatible = "amlogic,drm-subsystem";
		phandle = <0x10d>;
	};

	secmon {
		reserve_mem_size = <0x300000>;
		in_base_func = <0x82000020>;
		compatible = "amlogic, secmon";
		memory-region = <0x11>;
		out_base_func = <0x82000021>;
	};

	dmc_monitor {
		status = "okay";
		compatible = "amlogic, dmc_monitor";
		reg_base = <0xff639000>;
		interrupts = <0x00 0x33 0x01>;
	};

	firmware {

		android {
			compatible = "android,firmware";

			vbmeta {
				compatible = "android,vbmeta";
				by_name_prefix = "/dev/block";
				parts = "boot,system";
			};

			fstab {
				compatible = "android,fstab";

				system {
					mnt_flags = "ro,barrier=1,inode_readahead_blks=8";
					dev = "/dev/block/system";
					compatible = "android,system";
					fsmgr_flags = "wait,slotselect";
					type = "ext4";
				};
			};
		};
	};

	cpu_opp_table2 {
		opp-shared;
		compatible = "operating-points-v2";
		phandle = <0x0f>;

		opp04 {
			opp-microvolt = <0xb2778>;
			opp-hz = <0x00 0x3b9aca00>;
		};

		opp11 {
			opp-microvolt = <0xf1f18>;
			opp-hz = <0x00 0x71b9c500>;
		};

		opp03 {
			opp-microvolt = <0xb2778>;
			opp-hz = <0x00 0x27c19cc0>;
		};

		opp01 {
			opp-microvolt = <0xb2778>;
			opp-hz = <0x00 0xee6b280>;
		};

		opp06 {
			opp-microvolt = <0xb9ca8>;
			opp-hz = <0x00 0x5353c980>;
		};

		opp08 {
			opp-microvolt = <0xcae18>;
			opp-hz = <0x00 0x5fd82200>;
		};

		opp12 {
			opp-microvolt = <0xf6d38>;
			opp-hz = <0x00 0x7829b800>;
		};

		opp02 {
			opp-microvolt = <0xb2778>;
			opp-hz = <0x00 0x1dcd6500>;
		};

		opp00 {
			opp-microvolt = <0xb2778>;
			opp-hz = <0x00 0x5f5e100>;
		};

		opp10 {
			opp-microvolt = <0xef808>;
			opp-hz = <0x00 0x6b49d200>;
		};

		opp09 {
			opp-microvolt = <0xd2348>;
			opp-hz = <0x00 0x6590fa00>;
		};

		opp13 {
			opp-microvolt = <0xf6d38>;
			opp-hz = <0x00 0x7d2b7500>;
		};

		opp07 {
			opp-microvolt = <0xc11d8>;
			opp-hz = <0x00 0x5a1f4a00>;
		};

		opp05 {
			opp-microvolt = <0xb2778>;
			opp-hz = <0x00 0x47868c00>;
		};
	};

	interrupt-controller@2c001000 {
		#address-cells = <0x00>;
		compatible = "arm,cortex-a15-gic", "arm,cortex-a9-gic";
		reg = <0x00 0xffc01000 0x00 0x1000 0x00 0xffc02000 0x00 0x100>;
		interrupt-controller;
		#interrupt-cells = <0x03>;
		interrupts = <0x01 0x09 0xf04>;
		phandle = <0x01>;
	};

	pinctrl@ff634480 {
		#address-cells = <0x02>;
		compatible = "amlogic,meson-g12a-periphs-pinctrl";
		ranges;
		#size-cells = <0x02>;
		phandle = <0x8d>;

		spotify_touch_gpio {
			phandle = <0xbb>;

			mux {
				function = "gpio_periphs";
				drive-strength = "1";
				groups = "GPIOZ_3", "GPIOZ_4";
			};
		};

		tdmout_a {
			phandle = <0x24>;

			mux {
				function = "tdma_out";
				groups = "tdma_sclk", "tdma_fs", "tdma_dout0";
			};
		};

		gen_clk_ee_z {
			phandle = <0xc4>;

			mux {
				function = "gen_clk_ee";
				drive-strength = <0x03>;
				groups = "gen_clk_ee_z";
			};
		};

		i2c1_pins3 {
			phandle = <0xa1>;

			mux {
				function = "i2c1";
				drive-strength = <0x02>;
				groups = "i2c1_sda_h6", "i2c1_sck_h7";
			};
		};

		spotify_touch_i2c {
			phandle = <0x19>;

			mux {
				function = "i2c0";
				drive-strength = "1";
				groups = "i2c0_sda_z0", "i2c0_sck_z1";
			};
		};

		spotify_disabled_pins_c {
			phandle = <0x4e>;

			mux {
				bias-pull-down;
				pins = "GPIOC_0", "GPIOC_1", "GPIOC_2", "GPIOC_3", "GPIOC_5", "GPIOC_6", "GPIOC_7";
				output-low;
			};
		};

		jtag_apee_pin {
			phandle = <0x18>;

			mux {
				function = "jtag_b";
				groups = "jtag_b_tdi", "jtag_b_tdo", "jtag_b_clk", "jtag_b_tms";
			};
		};

		clk12_24_z_pins {
			phandle = <0xc3>;

			mux {
				function = "clk12_24_ee";
				drive-strength = <0x03>;
				groups = "clk12_24_z";
			};
		};

		sdio_x_en_pins {
			phandle = <0x98>;

			mux {
				output-high;
				function = "sdio";
				groups = "sdio_dummy";
				bias-pull-up;
			};
		};

		sdio_clk_cmd_pins {
			phandle = <0x94>;

			mux {
				function = "sdio";
				drive-strength = <0x03>;
				input-enable;
				groups = "sdio_clk", "sdio_cmd";
				bias-pull-up;
			};
		};

		pwm_d_pins1 {
			phandle = <0xab>;

			mux {
				function = "pwm_d";
				groups = "pwm_d_x3";
			};
		};

		i2c0_pins1 {
			phandle = <0x9c>;

			mux {
				function = "i2c0";
				drive-strength = <0x02>;
				groups = "i2c0_sda_c", "i2c0_sck_c";
			};
		};

		external_eth_pins {
			phandle = <0xb9>;

			mux {
				function = "eth";
				drive-strength = <0x03>;
				groups = "eth_mdio", "eth_mdc", "eth_rgmii_rx_clk", "eth_rx_dv", "eth_rxd0", "eth_rxd1", "eth_rxd2_rgmii", "eth_rxd3_rgmii", "eth_rgmii_tx_clk", "eth_txen", "eth_txd0", "eth_txd1", "eth_txd2_rgmii", "eth_txd3_rgmii";
			};
		};

		cam_dvp_pins {
			phandle = <0xc5>;

			mux {
				function = "bt656";
				groups = "bt656_a_vs", "bt656_a_hs", "bt656_a_clk", "bt656_a_din0", "bt656_a_din1", "bt656_a_din2", "bt656_a_din3", "bt656_a_din4", "bt656_a_din5", "bt656_a_din6", "bt656_a_din7";
			};
		};

		internal_eth_pins {
			phandle = <0xb7>;

			mux {
				function = "eth";
				groups = "eth_link_led", "eth_act_led";
			};
		};

		pwm_d_pins2 {
			phandle = <0xac>;

			mux {
				function = "pwm_d";
				groups = "pwm_d_x6";
			};
		};

		sdio_x_all_pins {
			phandle = <0x97>;

			mux {
				function = "gpio_periphs";
				drive-strength = <0x03>;
				input-enable;
				groups = "GPIOX_0", "GPIOX_1", "GPIOX_2", "GPIOX_3", "GPIOX_5";
				bias-pull-up;
			};

			mux1 {
				output-high;
				function = "gpio_periphs";
				drive-strength = <0x03>;
				groups = "GPIOX_4";
				bias-pull-up;
			};
		};

		tdmin_a {
			phandle = <0x25>;

			mux {
				function = "tdma_in";
				groups = "tdma_din1";
			};
		};

		hdmitx_ddc {
			phandle = <0xb4>;

			mux {
				bias-disable;
				function = "hdmitx";
				drive-strength = <0x03>;
				groups = "hdmitx_sda", "hdmitx_sck";
			};
		};

		spicc0_pins_c {
			phandle = <0xb0>;

			mux {
				function = "spi0";
				drive-strength = <0x01>;
				groups = "spi0_mosi_c", "spi0_miso_c", "spi0_ss0_c", "spi0_clk_c";
			};
		};

		i2c0_pins3 {
			phandle = <0x9e>;

			mux {
				function = "i2c0";
				drive-strength = <0x02>;
				groups = "i2c0_sda_z7", "i2c0_sck_z8";
			};
		};

		emmc_clk_cmd_pins {
			phandle = <0x2b>;

			mux {
				function = "emmc";
				input-enable;
				groups = "emmc_clk", "emmc_cmd";
				bias-pull-up;
			};
		};

		spotify_rotary {
			phandle = <0x4c>;

			mux {
				bias-disable;
				pins = "GPIOZ_7", "GPIOZ_8", "GPIOZ_9";
				input-enable;
			};
		};

		pwm_b_pins2 {
			phandle = <0xa7>;

			mux {
				function = "pwm_b";
				groups = "pwm_b_x19";
			};
		};

		new_bl_pin {
			phandle = <0x10f>;

			mux {
				function = "gpio_periphs";
				pins = "GPIOH_5";
				drive-strength = "1";
				output-low;
			};
		};

		sdio_x_clk_cmd_pins {
			phandle = <0x96>;

			mux {
				function = "gpio_periphs";
				drive-strength = <0x03>;
				input-enable;
				groups = "GPIOX_5";
				bias-pull-up;
			};

			mux1 {
				output-high;
				function = "gpio_periphs";
				drive-strength = <0x03>;
				groups = "GPIOX_4";
				bias-pull-up;
			};
		};

		pwm_c_pins2 {
			phandle = <0xa9>;

			mux {
				function = "pwm_c";
				groups = "pwm_c_x5";
			};
		};

		emmc_conf_pull_done {
			phandle = <0x2d>;

			mux {
				bias-pull-down;
				function = "emmc";
				input-enable;
				groups = "emmc_nand_ds";
			};
		};

		b_uart {
			phandle = <0x28>;

			mux {
				function = "uart_b";
				groups = "uart_tx_b", "uart_rx_b";
			};
		};

		sd_all_pins {
			phandle = <0x8f>;

			mux {
				function = "sdcard";
				drive-strength = <0x03>;
				input-enable;
				groups = "sdcard_d0_c", "sdcard_d1_c", "sdcard_d2_c", "sdcard_d3_c", "sdcard_cmd_c";
				bias-pull-up;
			};

			mux1 {
				output-high;
				function = "sdcard";
				drive-strength = <0x03>;
				groups = "sdcard_clk_c";
				bias-pull-up;
			};
		};

		spotify_disabled_pins_a {
			phandle = <0x4d>;

			mux {
				bias-pull-down;
				pins = "GPIOA_10", "GPIOA_11", "GPIOA_12", "GPIOA_13";
				output-low;
			};
		};

		sd_clr_all_pins {
			phandle = <0x91>;

			mux {
				output-high;
				function = "gpio_periphs";
				groups = "GPIOC_0", "GPIOC_1", "GPIOC_2", "GPIOC_3", "GPIOC_5";
			};

			mux1 {
				function = "gpio_periphs";
				output-low;
				groups = "GPIOC_4";
			};
		};

		spotify_prox_gpio {
			phandle = <0x1b>;

			mux {
				bias-pull-down;
				pins = "GPIOZ_10";
			};
		};

		spicc0_pins_x {
			phandle = <0xaf>;

			mux {
				function = "spi0";
				drive-strength = <0x01>;
				groups = "spi0_mosi_x", "spi0_miso_x", "spi0_clk_x";
			};
		};

		spotify_bluetooth_host_wake_bt {
			bias-disable;
			pins = "GPIOX_7";
			output-enable;
			drive-strength = "1";
			phandle = <0xbe>;
		};

		pwm_e {
			phandle = <0xad>;

			mux {
				function = "pwm_e";
				groups = "pwm_e";
			};
		};

		i2c1_pins1 {
			phandle = <0x9f>;

			mux {
				function = "i2c1";
				drive-strength = <0x02>;
				groups = "i2c1_sda_x", "i2c1_sck_x";
			};
		};

		i2c0_pins2 {
			phandle = <0x9d>;

			mux {
				function = "i2c0";
				drive-strength = <0x02>;
				groups = "i2c0_sda_z0", "i2c0_sck_z1";
			};
		};

		bl_pwm_off_pin {
			phandle = <0x47>;

			mux {
				function = "gpio_periphs";
				pins = "GPIOH_5";
				drive-strength = "1";
				output-low;
			};
		};

		ao_to_sd_uart_pins {
			phandle = <0x93>;

			mux {
				function = "uart_ao_a_ee";
				input-enable;
				groups = "uart_ao_tx_a_c3", "uart_ao_rx_a_c2";
				bias-pull-up;
			};
		};

		spotify_lcd_reset_pin {
			phandle = <0xbc>;

			mux {
				bias-disable;
				function = "gpio_periphs";
				pins = "GPIOZ_5";
				drive-strength = "1";
			};
		};

		c_uart {
			phandle = <0x29>;

			mux {
				function = "uart_c";
				groups = "uart_tx_c", "uart_rx_c";
			};
		};

		sd_clk_cmd_pins {
			phandle = <0x8e>;

			mux {
				function = "sdcard";
				drive-strength = <0x03>;
				input-enable;
				groups = "sdcard_cmd_c";
				bias-pull-up;
			};

			mux1 {
				output-high;
				function = "sdcard";
				drive-strength = <0x03>;
				groups = "sdcard_clk_c";
				bias-pull-up;
			};
		};

		sdio_all_pins {
			phandle = <0x95>;

			mux {
				function = "sdio";
				drive-strength = <0x03>;
				input-enable;
				groups = "sdio_d0", "sdio_d1", "sdio_d2", "sdio_d3", "sdio_clk", "sdio_cmd";
				bias-pull-up;
			};
		};

		pwm_b_pins1 {
			phandle = <0xa6>;

			mux {
				function = "pwm_b";
				groups = "pwm_b_x7";
			};
		};

		a_uart {
			phandle = <0x27>;

			mux {
				function = "uart_a";
				groups = "uart_tx_a", "uart_rx_a", "uart_cts_a", "uart_rts_a";
			};
		};

		pwm_c_pins3 {
			phandle = <0xaa>;

			mux {
				function = "pwm_c";
				groups = "pwm_c_x8";
			};
		};

		rstoutput1 {
			phandle = <0xc1>;

			mux {
				output-high;
				pins = "GPIOZ_3";
				drive-strength = "1";
				bias-pull-up;
			};
		};

		spdifin {
			status = "disabled";
			phandle = <0xba>;
		};

		banks@ff6346c0 {
			#gpio-cells = <0x02>;
			reg = <0x00 0xff6346c0 0x00 0x40 0x00 0xff6344e8 0x00 0x18 0x00 0xff634520 0x00 0x18 0x00 0xff634440 0x00 0x4c 0x00 0xff634740 0x00 0x1c>;
			gpio-controller;
			reg-names = "mux", "pull", "pull-enable", "gpio", "drive-strength";
			phandle = <0x15>;
		};

		pwm_f_pins1 {
			phandle = <0xae>;

			mux {
				function = "pwm_f";
				groups = "pwm_f_x";
			};
		};

		sd_clr_noall_pins {
			phandle = <0x92>;

			mux {
				output-high;
				function = "gpio_periphs";
				groups = "GPIOC_0", "GPIOC_1", "GPIOC_4", "GPIOC_5";
			};
		};

		spotify_mfi_i2c_pins {
			phandle = <0x1d>;

			mux {
				bias-disable;
				function = "i2c3";
				drive-strength = <0x02>;
				groups = "i2c3_sda_a", "i2c3_sck_a";
			};
		};

		spotify_disabled_pins_h {
			phandle = <0x4f>;

			mux {
				bias-pull-down;
				pins = "GPIOH_0", "GPIOH_1", "GPIOH_2", "GPIOH_3", "GPIOH_6", "GPIOH_7", "GPIOH_8";
				output-low;
			};
		};

		all_nand_pins {
			phandle = <0x9a>;

			mux {
				function = "nand";
				input-enable;
				groups = "emmc_nand_d0", "emmc_nand_d1", "emmc_nand_d2", "emmc_nand_d3", "emmc_nand_d4", "emmc_nand_d5", "emmc_nand_d6", "emmc_nand_d7", "nand_ce0", "nand_ale", "nand_cle", "nand_wen_clk", "nand_ren_wr", "nand_rb0";
			};
		};

		pdmin {
			phandle = <0x26>;

			mux {
				function = "pdm";
				drive-strength = <0x01>;
				groups = "pdm_din0_a", "pdm_din1_a", "pdm_dclk_a";
			};
		};

		i2c3_pins1 {
			phandle = <0xa3>;

			mux {
				function = "i2c3";
				drive-strength = <0x02>;
				groups = "i2c3_sda_h", "i2c3_sck_h";
			};
		};

		bl_enable {
			phandle = <0xc2>;

			mux {
				output-high;
				function = "gpio_periphs";
				pins = "GPIOH_4";
				bias-pull-up;
			};
		};

		ee_ceca {
			phandle = <0xb5>;

			mux {
				function = "cec_ao_ee";
				groups = "cec_ao_a_ee";
			};
		};

		ee_cecb {
			phandle = <0xb6>;

			mux {
				function = "cec_ao_ee";
				groups = "cec_ao_b_ee";
			};
		};

		i2c3_pins2 {
			phandle = <0xa4>;

			mux {
				function = "i2c3";
				drive-strength = <0x02>;
				groups = "i2c3_sda_a", "i2c3_sck_a";
			};
		};

		rstoutput0 {
			phandle = <0xc0>;

			mux {
				bias-pull-down;
				pins = "GPIOZ_3";
				drive-strength = "1";
				output-low;
			};
		};

		spotify_bluetooth_bt_wake_host {
			bias-disable;
			pins = "GPIOX_6";
			input-enable;
			phandle = <0xbd>;
		};

		sd_1bit_pins {
			phandle = <0x90>;

			mux {
				function = "sdcard";
				drive-strength = <0x03>;
				input-enable;
				groups = "sdcard_d0_c", "sdcard_cmd_c";
				bias-pull-up;
			};

			mux1 {
				output-high;
				function = "sdcard";
				drive-strength = <0x03>;
				groups = "sdcard_clk_c";
				bias-pull-up;
			};
		};

		hdmitx_hpd_gpio {
			phandle = <0xb3>;

			mux {
				bias-disable;
				function = "gpio_periphs";
				groups = "GPIOH_1";
			};
		};

		pwm_c_pins1 {
			phandle = <0xa8>;

			mux {
				function = "pwm_c";
				groups = "pwm_c_c4";
			};
		};

		spotify_imu_gpio {
			phandle = <0x1c>;

			mux {
				bias-pull-down;
				pins = "GPIOZ_12", "GPIOZ_13";
			};
		};

		internal_gpio_pins {
			phandle = <0xb8>;

			mux {
				bias-disable;
				function = "gpio_periphs";
				input-enable;
				groups = "GPIOZ_14", "GPIOZ_15";
			};
		};

		nand_cs {
			phandle = <0x9b>;

			mux {
				function = "nand";
				groups = "nand_ce0";
			};
		};

		emmc_conf_pull_up {
			phandle = <0x2c>;

			mux {
				function = "emmc";
				input-enable;
				groups = "emmc_nand_d7", "emmc_nand_d6", "emmc_nand_d5", "emmc_nand_d4", "emmc_nand_d3", "emmc_nand_d2", "emmc_nand_d1", "emmc_nand_d0", "emmc_clk", "emmc_cmd";
				bias-pull-up;
			};
		};

		i2c2_pins1 {
			phandle = <0xa2>;

			mux {
				function = "i2c2";
				drive-strength = <0x02>;
				groups = "i2c2_sda_x", "i2c2_sck_x";
			};
		};

		pwm_f_pins2 {
			phandle = <0x46>;

			mux {
				function = "pwm_f";
				groups = "pwm_f_h";
			};
		};

		spicc1_pins {
			phandle = <0xb1>;

			mux {
				function = "spi1";
				drive-strength = <0x01>;
				groups = "spi1_mosi", "spi1_miso", "spi1_clk";
			};
		};

		pwm_a {
			phandle = <0xa5>;

			mux {
				function = "pwm_a";
				groups = "pwm_a";
			};
		};

		i2c1_pins2 {
			phandle = <0xa0>;

			mux {
				function = "i2c1";
				drive-strength = <0x02>;
				groups = "i2c1_sda_h2", "i2c1_sck_h3";
			};
		};

		sdio_x_clr_pins {
			phandle = <0x99>;

			mux {
				function = "gpio_periphs";
				output-low;
				groups = "GPIOV_0";
				bias-pull-up;
			};

			mux1 {
				function = "gpio_periphs";
				output-low;
				groups = "GPIOX_4";
			};
		};

		spotify_buttons {
			phandle = <0x4b>;

			mux {
				bias-disable;
				pins = "GPIOA_0", "GPIOA_1", "GPIOA_2", "GPIOA_3", "GPIOAO_3", "GPIOA_5";
				input-enable;
			};
		};

		eint@0 {
			phandle = <0xbf>;

			mux {
				pins = "GPIOZ_4";
				bias-pull-up;
			};
		};

		i2c2_pins2 {
			phandle = <0x1a>;

			mux {
				function = "i2c2";
				drive-strength = <0x02>;
				groups = "i2c2_sda_z", "i2c2_sck_z";
			};
		};

		hdmitx_hpd {
			phandle = <0xb2>;

			mux {
				bias-disable;
				function = "hdmitx";
				groups = "hdmitx_hpd_in";
			};
		};
	};

	usb3phy@ffe09080 {
		gpio-vbus-power = "GPIOH_6";
		clock-names = "pcie_refpll";
		phy-reg = <0xff646000>;
		status = "disabled";
		compatible = "amlogic, amlogic-new-usb3-v2";
		phy-reg-size = <0x2000>;
		reg = <0x00 0xffe09080 0x00 0x20>;
		clocks = <0x02 0x18>;
		usb2-phy-reg-size = <0x80>;
		otg = <0x01>;
		gpios = <0x15 0x17 0x00>;
		usb2-phy-reg = <0xffe09000>;
		interrupts = <0x00 0x10 0x04>;
		portnum = <0x01>;
		phandle = <0x14>;
	};

	dummy {
		#sound-dai-cells = <0x00>;
		status = "okay";
		compatible = "amlogic, aml_dummy_codec";
		phandle = <0x71>;
	};

	meson-amvideom {
		dev_name = "amvideom";
		status = "okay";
		compatible = "amlogic, amvideom";
		interrupt-names = "vsync";
		interrupts = <0x00 0x03 0x01>;
	};

	eqdrc {
		channel_mask = <0x03>;
		eqdrc_module = <0x01>;
		lane_mask = <0x01>;
		phandle = <0x6f>;
	};

	thermal-sensor@3 {
		io-channels = <0x50 0x03>;
		temperature-lookup-table = <0x14c08 0x37e 0x13880 0x36e 0x124f8 0x35c 0x11170 0x347 0xfde8 0x32f 0xea60 0x315 0xd6d8 0x2f7 0xc350 0x2d6 0xafc8 0x2b2 0x9c40 0x28a 0x88b8 0x25f 0x7530 0x230 0x61a8 0x200 0x4e20 0x1ce 0x3a98 0x19b 0x2710 0x168 0x1388 0x137 0x00 0x109 0xffffec78 0xdd 0xffffd8f0 0xb6 0xffffc568 0x93 0xffffb1e0 0x75 0xffff9e58 0x5c 0xffff8ad0 0x46 0xffff7748 0x35 0xffff63c0 0x28>;
		compatible = "generic-adc-thermal";
		#thermal-sensor-cells = <0x00>;
		io-channel-names = "sensor-channel";
		phandle = <0x36>;
	};

	reserved-memory {
		#address-cells = <0x02>;
		ranges;
		#size-cells = <0x02>;

		ramoops@0x07400000 {
			record-size = <0x8000>;
			compatible = "ramoops";
			reg = <0x00 0x7400000 0x00 0x100000>;
			ftrace-size = <0x20000>;
			console-size = <0x8000>;
		};

		linux,meson-fb {
			alignment = <0x00 0x400000>;
			reusable;
			compatible = "shared-dma-pool";
			size = <0x00 0x800000>;
			alloc-ranges = <0x00 0x1f800000 0x00 0x800000>;
			phandle = <0x2a>;
		};

		linux,codec_mm_reserved {
			alignment = <0x00 0x100000>;
			compatible = "amlogic, codec-mm-reserved";
			size = <0x00 0x00>;
			phandle = <0x52>;
		};

		linux,secmon {
			alignment = <0x00 0x400000>;
			reusable;
			compatible = "shared-dma-pool";
			size = <0x00 0x400000>;
			alloc-ranges = <0x00 0x5000000 0x00 0x400000>;
			phandle = <0x11>;
		};

		linux,codec_mm_cma {
			linux,contiguous-region;
			alignment = <0x00 0x400000>;
			reusable;
			compatible = "shared-dma-pool";
			size = <0x00 0x13400000>;
			phandle = <0x51>;
		};

		linux,ion-dev {
			alignment = <0x00 0x400000>;
			reusable;
			compatible = "shared-dma-pool";
			size = <0x00 0x8000000>;
			phandle = <0x22>;
		};

		linux,secos {
			no-map;
			status = "disable";
			compatible = "amlogic, aml_secos_memory";
			reg = <0x00 0x5300000 0x00 0x2000000>;
			phandle = <0x101>;
		};

		linux,di_cma {
			alignment = <0x00 0x400000>;
			reusable;
			compatible = "shared-dma-pool";
			size = <0x00 0x2800000>;
			phandle = <0x54>;
		};

		linux,ppmgr {
			compatible = "shared-dma-pool";
			size = <0x00 0x00>;
			phandle = <0x53>;
		};

		linux,vm0_cma {
			alignment = <0x00 0x400000>;
			reusable;
			compatible = "shared-dma-pool";
			size = <0x00 0x2000000>;
			phandle = <0x55>;
		};
	};

	ram-dump {
		status = "okay";
		compatible = "amlogic, ram_dump";
		store_device = "data";
		reg = <0x00 0xff6345e0 0x00 0x04>;
		reg-names = "PREG_STICKY_REG8";
	};

	vout {
		dev_name = "vout";
		status = "okay";
		compatible = "amlogic, vout";
	};

	unifykey {
		unifykey-index-3 = <0x59>;
		unifykey-index-8 = <0x5e>;
		unifykey-index-10 = <0x60>;
		unifykey-index-16 = <0x66>;
		unifykey-index-15 = <0x65>;
		status = "ok";
		compatible = "amlogic, unifykey";
		unifykey-index-1 = <0x57>;
		unifykey-index-11 = <0x61>;
		unifykey-index-12 = <0x62>;
		unifykey-index-17 = <0x67>;
		unifykey-index-6 = <0x5c>;
		unifykey-index-2 = <0x58>;
		unifykey-index-13 = <0x63>;
		unifykey-index-0 = <0x56>;
		unifykey-index-14 = <0x64>;
		unifykey-index-9 = <0x5f>;
		unifykey-index-7 = <0x5d>;
		unifykey-num = <0x12>;
		unifykey-index-5 = <0x5b>;
		unifykey-index-4 = <0x5a>;

		key_14 {
			key-permit = "read", "write", "del";
			key-name = "attestationkeybox";
			key-device = "secure";
			phandle = <0x64>;
		};

		key_13 {
			key-permit = "read", "write", "del";
			key-name = "prprivkeybox";
			key-device = "secure";
			phandle = <0x63>;
		};

		key_4 {
			key-type = "mac";
			key-permit = "read", "write", "del";
			key-name = "mac_bt";
			key-device = "normal";
			phandle = <0x5a>;
		};

		key_7 {
			key-permit = "read", "write", "del";
			key-name = "hdcp2_rx";
			key-device = "normal";
			phandle = <0x5d>;
		};

		key_1 {
			key-permit = "read", "write", "del";
			key-name = "mac";
			key-device = "normal";
			phandle = <0x57>;
		};

		key_3 {
			key-permit = "write";
			key-name = "secure_boot_set";
			key-device = "efuse";
			phandle = <0x59>;
		};

		key_8 {
			key-permit = "read", "write", "del";
			key-name = "widevinekeybox";
			key-device = "secure";
			phandle = <0x5e>;
		};

		key_11 {
			key-permit = "read", "write", "del";
			key-name = "PlayReadykeybox25";
			key-device = "secure";
			phandle = <0x61>;
		};

		key_6 {
			key-permit = "read", "write", "del";
			key-name = "hdcp2_tx";
			key-device = "normal";
			phandle = <0x5c>;
		};

		key_15 {
			key-permit = "read", "write", "del";
			key-name = "region_code";
			key-device = "normal";
			phandle = <0x65>;
		};

		key_2 {
			key-type = "sha1";
			key-permit = "read", "write", "del";
			key-name = "hdcp";
			key-device = "secure";
			phandle = <0x58>;
		};

		key_17 {
			key-permit = "read", "write", "del";
			key-name = "f_serial";
			key-device = "normal";
			phandle = <0x67>;
		};

		key_10 {
			key-permit = "read", "write", "del";
			key-name = "hdcp22_fw_private";
			key-device = "secure";
			phandle = <0x60>;
		};

		key_16 {
			key-permit = "read", "write", "del";
			key-name = "netflix_mgkid";
			key-device = "secure";
			phandle = <0x66>;
		};

		key_0 {
			key-permit = "read", "write", "del";
			key-name = "usid";
			key-device = "normal";
			phandle = <0x56>;
		};

		key_12 {
			key-permit = "read", "write", "del";
			key-name = "prpubkeybox";
			key-device = "secure";
			phandle = <0x62>;
		};

		key_5 {
			key-type = "mac";
			key-permit = "read", "write", "del";
			key-name = "mac_wifi";
			key-device = "normal";
			phandle = <0x5b>;
		};

		key_9 {
			key-permit = "read", "write", "del";
			key-name = "deviceid";
			key-device = "normal";
			phandle = <0x5f>;
		};
	};

	ionvideo {
		dev_name = "ionvideo";
		status = "okay";
		compatible = "amlogic, ionvideo";
	};

	backlight {
		bl_pwm_config = <0x48>;
		pinctrl-0 = <0x46>;
		pinctrl-names = "pwm_on", "pwm_off";
		key_valid = <0x00>;
		status = "okay";
		compatible = "amlogic, backlight-g12a";
		bl-gpios = <0x15 0x15 0x00 0x15 0x16 0x00>;
		pinctrl_version = <0x02>;
		bl_gpio_names = "GPIOH_4", "GPIOH_5";
		pinctrl-1 = <0x10f>;

		backlight_1 {
			bl_extern_index = <0x00>;
			bl_name = "bl_extern";
			bl_level_default_uboot_kernel = <0x64 0x64>;
			index = <0x01>;
			bl_power_attr = <0x01 0x01 0x00 0xc8 0xc8>;
			bl_ctrl_method = <0x04>;
			bl_level_attr = <0xff 0x0a 0x80 0x80>;
		};

		backlight_0 {
			bl_pwm_en_sequence_reverse = <0x00>;
			bl_pwm_attr = <0x00 0x7530 0x64 0x00>;
			bl_name = "backlight_pwm";
			bl_level_default_uboot_kernel = <0x64 0x64>;
			index = <0x00>;
			bl_power_attr = <0x00 0x01 0x00 0xc8 0xc8>;
			bl_pwm_power = <0x01 0x01 0x0a 0x0a>;
			bl_ctrl_method = <0x01>;
			bl_pwm_port = "PWM_F";
			bl_level_attr = <0xff 0x01 0x80 0x80>;
		};
	};

	mhu@c883c400 {
		compatible = "amlogic, meson_mhu";
		mbox-names = "cpu_to_scp_low", "cpu_to_scp_high";
		reg = <0x00 0xff63c400 0x00 0x4c 0x00 0xfffe7000 0x00 0x800>;
		#mbox-cells = <0x01>;
		mboxes = <0x12 0x00 0x12 0x01>;
		interrupts = <0x00 0xd1 0x01 0x00 0xd2 0x01>;
		phandle = <0x12>;
	};

	dwc3@ff500000 {
		clock-names = "dwc_general";
		status = "okay";
		compatible = "synopsys, dwc3";
		cpu-type = "gxl";
		reg = <0x00 0xff500000 0x00 0x100000>;
		clocks = <0x02 0x41>;
		clock-src = "usb3.0";
		interrupts = <0x00 0x1e 0x04>;
		usb-phy = <0x13 0x14>;
		phandle = <0xc7>;
	};

	vdin0 {
		dev_name = "vdin0";
		status = "disabled";
		compatible = "amlogic, vdin";
		vdin_id = <0x00>;
		flag_cma = <0x00>;
		rdma-irq = <0x02>;
		interrupts = <0x00 0x53 0x01>;
		phandle = <0xe4>;
		reserve-iomap = "true";
	};

	soc {
		#address-cells = <0x02>;
		compatible = "simple-bus";
		ranges;
		#size-cells = <0x02>;

		audiobus@0xff642000 {
			#address-cells = <0x02>;
			compatible = "amlogic, audio-controller", "simple-bus";
			ranges = <0x00 0x00 0x00 0xff642000 0x00 0x2000>;
			#size-cells = <0x02>;
			reg = <0x00 0xff642000 0x00 0x2000>;
			phandle = <0xde>;

			loopback {
				datalb-lane-mask-in = <0x00 0x01>;
				clock-names = "datalb_mpll";
				datain_src = <0x04>;
				datalb_chmask = <0x03>;
				lb_mode = <0x00>;
				status = "okay";
				compatible = "amlogic, snd-loopback";
				datalb_src = <0x00>;
				clocks = <0x02 0x0d>;
				datalb_chnum = <0x02>;
				datain_chmask = <0x3f>;
				datain_chnum = <0x08>;
				phandle = <0x6d>;
			};

			audio_clocks {
				#clock-cells = <0x01>;
				compatible = "amlogic, g12a-audio-clocks";
				reg = <0x00 0x00 0x00 0xb0>;
				phandle = <0x23>;
			};

			resample {
				clock-names = "resample_pll", "resample_src", "resample_clk";
				status = "okay";
				compatible = "amlogic, g12a-resample";
				clocks = <0x02 0x0f 0x23 0x1c 0x23 0x24>;
				resample_module = <0x04>;
				phandle = <0xe0>;
			};

			ddr_manager {
				compatible = "amlogic, g12a-audio-ddr-manager";
				interrupt-names = "toddr_a", "toddr_b", "toddr_c", "frddr_a", "frddr_b", "frddr_c";
				interrupts = <0x00 0x94 0x01 0x00 0x95 0x01 0x00 0x96 0x01 0x00 0x98 0x01 0x00 0x99 0x01 0x00 0x9a 0x01>;
			};

			tdma {
				dai-tdm-clk-sel = <0x00>;
				pinctrl-0 = <0x24 0x25>;
				clock-names = "mclk", "clk_srcpll";
				pinctrl-names = "tdm_pins";
				#sound-dai-cells = <0x00>;
				compatible = "amlogic, g12a-snd-tdma";
				dai-tdm-lane-slot-mask-in = <0x00 0x01>;
				clocks = <0x23 0x17 0x02 0x0c>;
				phandle = <0xdf>;
				dai-tdm-oe-lane-slot-mask-out = <0x01 0x00>;
			};

			pdm {
				pinctrl-0 = <0x26>;
				clock-names = "gate", "sysclk_srcpll", "dclk_srcpll", "pdm_dclk", "pdm_sysclk";
				pinctrl-names = "pdm_pins";
				#sound-dai-cells = <0x00>;
				filter_mode = <0x01>;
				status = "okay";
				compatible = "amlogic, g12a-snd-pdm";
				clocks = <0x23 0x01 0x02 0x03 0x02 0x0f 0x23 0x1f 0x23 0x20>;
				phandle = <0x70>;
			};
		};

		hiubus@ff63c000 {
			#address-cells = <0x02>;
			compatible = "simple-bus";
			ranges = <0x00 0x00 0x00 0xff63c000 0x00 0x2000>;
			#size-cells = <0x02>;
			reg = <0x00 0xff63c000 0x00 0x2000>;
			phandle = <0xdd>;

			clock-controller@0 {
				#clock-cells = <0x01>;
				compatible = "amlogic,g12a-clkc";
				reg = <0x00 0x00 0x00 0x320>;
				phandle = <0x02>;
			};
		};

		cbus@ffd00000 {
			#address-cells = <0x02>;
			compatible = "simple-bus";
			ranges = <0x00 0x00 0x00 0xffd00000 0x00 0x26000>;
			#size-cells = <0x02>;
			reg = <0x00 0xffd00000 0x00 0x26000>;
			phandle = <0xca>;

			i2c@1e000 {
				clock-names = "clk_i2c";
				#address-cells = <0x01>;
				status = "disabled";
				compatible = "amlogic,meson-g12a-i2c";
				#size-cells = <0x00>;
				reg = <0x00 0x1e000 0x00 0x20>;
				clocks = <0x02 0x2a>;
				interrupts = <0x00 0xd6 0x01 0x00 0x5c 0x01>;
				phandle = <0xcf>;
			};

			i2c@1c000 {
				pinctrl-0 = <0x1d>;
				clock-names = "clk_i2c";
				pinctrl-names = "default";
				#address-cells = <0x01>;
				status = "okay";
				compatible = "amlogic,meson-g12a-i2c";
				#size-cells = <0x00>;
				reg = <0x00 0x1c000 0x00 0x20>;
				clocks = <0x02 0x2a>;
				clock-frequency = <0x61a80>;
				interrupts = <0x00 0x27 0x01 0x00 0x5f 0x01>;
				phandle = <0xd1>;

				mfi@10 {
					compatible = "apple_mfi_auth";
					reg = <0x10>;
				};
			};

			i2c@1f000 {
				pinctrl-0 = <0x19>;
				clock-names = "clk_i2c";
				pinctrl-names = "default";
				#address-cells = <0x01>;
				status = "okay";
				compatible = "amlogic,meson-g12a-i2c";
				#size-cells = <0x00>;
				reg = <0x00 0x1f000 0x00 0x20>;
				clocks = <0x02 0x2a>;
				clock-frequency = <0x61a80>;
				interrupts = <0x00 0x15 0x01 0x00 0x5b 0x01>;
				phandle = <0xce>;

				tlsc6x_ts@2e {
					TP_MAX_Y = <0x320>;
					status = "okay";
					compatible = "tlsc6x,tlsc6x_ts";
					TP_MAX_X = <0x1e0>;
					reg = <0x2e>;
					reset-gpio = <0x15 0x04 0x00>;
					polling-mode = <0x00>;
					irq-gpio = <0x15 0x05 0x00>;
				};
			};

			i2c@1d000 {
				pinctrl-0 = <0x1a 0x1b 0x1c>;
				clock-names = "clk_i2c";
				pinctrl-names = "default";
				#address-cells = <0x01>;
				status = "okay";
				compatible = "amlogic,meson-g12a-i2c";
				#size-cells = <0x00>;
				reg = <0x00 0x1d000 0x00 0x20>;
				clocks = <0x02 0x2a>;
				clock-frequency = <0x61a80>;
				interrupts = <0x00 0xd7 0x01 0x00 0x5e 0x01>;
				phandle = <0xd0>;

				max20332@35 {
					reg = <0x35>;
				};

				lis2dh12@18 {
					compatible = "st,lis2dh12-accel";
					reg = <0x18>;
				};

				tmd27721@39 {
					enable-proxy = "false";
					compatible = "amstaos,tmd2772";
					reg = <0x39>;
					enable-als = "true";
				};
			};

			spi@13000 {
				clock-names = "core", "comp";
				#address-cells = <0x01>;
				status = "disabled";
				compatible = "amlogic,meson-g12a-spicc";
				#size-cells = <0x00>;
				reg = <0x00 0x13000 0x00 0x44>;
				clocks = <0x02 0x29 0x02 0xd1>;
				interrupts = <0x00 0x51 0x04>;
				phandle = <0xd2>;
			};

			spi@15000 {
				clock-names = "core", "comp";
				#address-cells = <0x01>;
				status = "disabled";
				compatible = "amlogic,meson-g12a-spicc";
				#size-cells = <0x00>;
				reg = <0x00 0x15000 0x00 0x44>;
				clocks = <0x02 0x2f 0x02 0xd5>;
				interrupts = <0x00 0x5a 0x04>;
				phandle = <0xd3>;
			};

			pwm@1b000 {
				#pwm-cells = <0x03>;
				clock-names = "clkin0", "clkin1", "clkin2", "clkin3";
				status = "disabled";
				compatible = "amlogic,g12a-ee-pwm";
				reg = <0x00 0x1b000 0x00 0x20>;
				clocks = <0x16 0x16 0x16 0x16>;
				phandle = <0xcc>;
			};

			interrupt-controller@f080 {
				status = "okay";
				compatible = "amlogic,meson-gpio-intc-ext", "amlogic,meson-g12a-gpio-intc";
				reg = <0x00 0xf080 0x00 0x10>;
				amlogic,channel-interrupts = <0x40 0x41 0x42 0x43 0x44 0x45 0x46 0x47>;
				interrupt-controller;
				#interrupt-cells = <0x02>;
				phandle = <0xcb>;
			};

			pwm@19000 {
				#pwm-cells = <0x03>;
				clock-names = "clkin0", "clkin1", "clkin2", "clkin3";
				status = "okay";
				compatible = "amlogic,g12a-ee-pwm";
				reg = <0x00 0x19000 0x00 0x20>;
				clocks = <0x16 0x16 0x16 0x16>;
				phandle = <0x49>;
			};

			pwm@1a000 {
				#pwm-cells = <0x03>;
				clock-names = "clkin0", "clkin1", "clkin2", "clkin3";
				status = "disabled";
				compatible = "amlogic,g12a-ee-pwm";
				reg = <0x00 0x1a000 0x00 0x20>;
				clocks = <0x16 0x16 0x16 0x16>;
				phandle = <0xcd>;
			};

			meson_clk_msr {
				ringctrl = <0xff6345fc>;
				compatible = "amlogic, gxl_measure";
				reg = <0x00 0x18004 0x00 0x04 0x00 0x1800c 0x00 0x04>;
			};
		};

		periphs@ff634400 {
			#address-cells = <0x02>;
			compatible = "simple-bus";
			ranges = <0x00 0x00 0x00 0xff634400 0x00 0x400>;
			#size-cells = <0x02>;
			reg = <0x00 0xff634400 0x00 0x400>;
			phandle = <0xdc>;
		};

		ion_dev {
			compatible = "amlogic, ion_dev";
			memory-region = <0x22>;
		};

		aobus@ff800000 {
			#address-cells = <0x02>;
			compatible = "simple-bus";
			ranges = <0x00 0x00 0x00 0xff800000 0x00 0xb000>;
			#size-cells = <0x02>;
			reg = <0x00 0xff800000 0x00 0xb000>;
			phandle = <0xd4>;

			i2c@5000 {
				clock-names = "clk_i2c";
				#address-cells = <0x01>;
				status = "disabled";
				compatible = "amlogic,meson-g12a-i2c";
				#size-cells = <0x00>;
				reg = <0x00 0x5000 0x00 0x20>;
				clocks = <0x02 0x2a>;
				interrupts = <0x00 0xc3 0x01 0x00 0xc9 0x01>;
				phandle = <0xd7>;
			};

			pwm@7000 {
				#pwm-cells = <0x03>;
				clock-names = "clkin0", "clkin1", "clkin2", "clkin3";
				status = "disabled";
				compatible = "amlogic,g12a-ao-pwm";
				reg = <0x00 0x7000 0x00 0x20>;
				clocks = <0x16 0x16 0x16 0x16>;
				phandle = <0xd6>;
			};

			serial@3000 {
				support-sysrq = <0x00>;
				pinctrl-0 = <0x1f>;
				clock-names = "clk_uart";
				fifosize = <0x40>;
				pinctrl-names = "default";
				status = "okay";
				compatible = "amlogic, meson-uart";
				reg = <0x00 0x3000 0x00 0x18>;
				clocks = <0x16>;
				interrupts = <0x00 0xc1 0x01>;
				xtal_tick_en = <0x02>;
				phandle = <0xd9>;
			};

			meson-irblaster@14c {
				pinctrl-0 = <0x21>;
				pinctrl-names = "default";
				status = "disabled";
				compatible = "amlogic, meson_irblaster";
				reg = <0x00 0x14c 0x00 0x10 0x00 0x40 0x00 0x04>;
				interrupts = <0x00 0xc6 0x01>;
				#irblaster-cells = <0x02>;
				phandle = <0xdb>;
			};

			i2c_slave@6000 {
				pinctrl-0 = <0x1e>;
				pinctrl-names = "default";
				status = "disabled";
				compatible = "amlogic, meson-i2c-slave";
				reg = <0x00 0x6000 0x00 0x20>;
				interrupts = <0x00 0xc2 0x01>;
				phandle = <0xd8>;
			};

			serial@4000 {
				pinctrl-0 = <0x20>;
				clock-names = "clk_uart";
				fifosize = <0x40>;
				pinctrl-names = "default";
				status = "disabled";
				compatible = "amlogic, meson-uart";
				reg = <0x00 0x4000 0x00 0x18>;
				clocks = <0x16>;
				interrupts = <0x00 0xc5 0x01>;
				phandle = <0xda>;
			};

			cpu_version {
				reg = <0x00 0x220 0x00 0x04>;
			};

			pwm@2000 {
				#pwm-cells = <0x03>;
				clock-names = "clkin0", "clkin1", "clkin2", "clkin3";
				status = "okay";
				compatible = "amlogic,g12a-ao-pwm";
				reg = <0x00 0x2000 0x00 0x20>;
				clocks = <0x16 0x16 0x16 0x16>;
				phandle = <0x38>;
			};

			clock-controller@0 {
				#clock-cells = <0x01>;
				compatible = "amlogic,g12a-aoclkc";
				reg = <0x00 0x00 0x00 0x320>;
				phandle = <0xd5>;
			};
		};
	};

	vpu {
		clock-names = "vapb_clk", "vpu_intr_gate", "vpu_clk0", "vpu_clk1", "vpu_clk";
		dev_name = "vpu";
		status = "okay";
		compatible = "amlogic, vpu-g12a";
		clocks = <0x02 0x95 0x02 0x4c 0x02 0x87 0x02 0x8b 0x02 0x8c>;
		clk_level = <0x07>;
	};

	deinterlace {
		clock-range = <0x14e 0x29b>;
		clock-names = "vpu_clkb_tmp_composite", "vpu_clkb_composite";
		nrds-enable = <0x01>;
		status = "okay";
		compatible = "amlogic, deinterlace";
		memory-region = <0x54>;
		clocks = <0x02 0x9b 0x02 0x9c>;
		post-wr-support = <0x01>;
		buffer-size = <0x3e2c40>;
		interrupt-names = "pre_irq", "post_irq";
		flag_cma = <0x01>;
		nr10bit-support = <0x01>;
		pps-enable = <0x01>;
		interrupts = <0x00 0x2e 0x01 0x00 0x28 0x01>;
	};

	ge2d {
		clock-names = "clk_vapb_0", "clk_ge2d", "clk_ge2d_gate";
		dev_name = "ge2d";
		status = "okay";
		compatible = "amlogic, ge2d-g12a";
		reg = <0x00 0xff940000 0x00 0x10000>;
		clocks = <0x02 0x95 0x02 0x3d 0x02 0x96>;
		interrupt-names = "ge2d";
		interrupts = <0x00 0x92 0x01>;
	};

	aml_dma {
		compatible = "amlogic,aml_txlx_dma";
		reg = <0x00 0xff63e000 0x00 0x48>;
		interrupts = <0x00 0xb4 0x01>;

		aml_aes {
			dev_name = "aml_aes_dma";
			status = "okay";
			compatible = "amlogic,aes_g12a_dma";
		};

		aml_tdes {
			dev_name = "aml_tdes_dma";
			status = "okay";
			compatible = "amlogic,tdes_dma";
		};

		aml_sha {
			dev_name = "aml_sha_dma";
			status = "okay";
			compatible = "amlogic,sha_dma";
		};
	};

	partitions {
		part-2 = <0x3c>;
		part-11 = <0x45>;
		part-3 = <0x3d>;
		part-1 = <0x3b>;
		part-5 = <0x3f>;
		part-9 = <0x43>;
		part-10 = <0x44>;
		part-8 = <0x42>;
		part-7 = <0x41>;
		part-4 = <0x3e>;
		part-0 = <0x3a>;
		part-6 = <0x40>;
		parts = <0x0c>;
		phandle = <0xff>;

		boot_b {
			mask = <0x01>;
			size = <0x00 0x1000000>;
			pname = "boot_b";
			phandle = <0x40>;
		};

		data {
			mask = <0x04>;
			size = <0xffffffff 0xffffffff>;
			pname = "data";
			phandle = <0x45>;
		};

		vbmeta_b {
			mask = <0x01>;
			size = <0x00 0x100000>;
			pname = "vbmeta_b";
			phandle = <0x3e>;
		};

		vbmeta_a {
			mask = <0x01>;
			size = <0x00 0x100000>;
			pname = "vbmeta_a";
			phandle = <0x3d>;
		};

		dtbo_b {
			mask = <0x01>;
			size = <0x00 0x400000>;
			pname = "dtbo_b";
			phandle = <0x3c>;
		};

		system_a {
			mask = <0x01>;
			size = <0x00 0x2040b000>;
			pname = "system_a";
			phandle = <0x41>;
		};

		logo {
			mask = <0x01>;
			size = <0x00 0x800000>;
			pname = "logo";
			phandle = <0x3a>;
		};

		settings {
			mask = <0x01>;
			size = <0x00 0x10000000>;
			pname = "settings";
			phandle = <0x44>;
		};

		misc {
			mask = <0x01>;
			size = <0x00 0x800000>;
			pname = "misc";
			phandle = <0x43>;
		};

		boot_a {
			mask = <0x01>;
			size = <0x00 0x1000000>;
			pname = "boot_a";
			phandle = <0x3f>;
		};

		dtbo_a {
			mask = <0x01>;
			size = <0x00 0x400000>;
			pname = "dtbo_a";
			phandle = <0x3b>;
		};

		system_b {
			mask = <0x01>;
			size = <0x00 0x2040b000>;
			pname = "system_b";
			phandle = <0x42>;
		};
	};

	disabled-pins {
		pinctrl-0 = <0x4d 0x4e 0x4f>;
		pinctrl-names = "default";
		status = "okay";
	};

	vdin1 {
		dev_name = "vdin1";
		status = "disabled";
		compatible = "amlogic, vdin";
		vdin_id = <0x01>;
		flag_cma = <0x00>;
		rdma-irq = <0x04>;
		interrupts = <0x00 0x55 0x01>;
		phandle = <0xe5>;
		reserve-iomap = "true";
	};

	gpio-keys {
		pinctrl-0 = <0x4b>;
		pinctrl-names = "default";
		poll-interval = <0x28>;
		status = "okay";
		compatible = "gpio-keys-polled";

		mute {
			linux,code = <0x32>;
			label = "GPIO Key mute";
			gpios = <0x4a 0x03 0x01>;
		};

		preset4 {
			linux,code = <0x05>;
			label = "GPIO Key preset4";
			gpios = <0x15 0x35 0x01>;
		};

		back {
			linux,code = <0x01>;
			label = "GPIO Key back";
			gpios = <0x15 0x37 0x01>;
		};

		preset2 {
			linux,code = <0x03>;
			label = "GPIO Key preset2";
			gpios = <0x15 0x33 0x01>;
		};

		select {
			linux,code = <0x1c>;
			label = "GPIO Key select";
			gpios = <0x15 0x08 0x01>;
		};

		preset1 {
			linux,code = <0x02>;
			label = "GPIO Key preset1";
			gpios = <0x15 0x32 0x01>;
		};

		preset3 {
			linux,code = <0x04>;
			label = "GPIO Key preset3";
			gpios = <0x15 0x34 0x01>;
		};
	};

	auge_sound {
		avout_mute-gpios = <0x4a 0x02 0x00>;
		compatible = "amlogic, g12a-sound-card";
		aml-audio-card,loopback = <0x6d>;
		aml-audio-card,name = "AML-AUGESOUND";
		aml-audio-card,aux-devs = <0x6e>;
		aml-audio-card,effect = <0x6f>;

		aml-audio-card,dai-link@3 {
			mclk-fs = <0x40>;
			aml-audio-card,routing = "PDM_DIN0", "Left Microphones", "PDM_DIN1", "Right Microphones";
			aml-audio-card,widgets = "Microphone", "Left Microphones", "Microphone", "Right Microphones";
			suffix-name = "alsaPORT-pdm";

			codec {
				sound-dai = <0x71>;
			};

			cpu {
				sound-dai = <0x70>;
			};
		};
	};

	vdac {
		status = "okay";
		compatible = "amlogic, vdac-g12a";
	};

	meson-fb {
		pxp_mode = <0x00>;
		display_size_default = <0x1e0 0x320 0x1e0 0x640 0x18>;
		logo_addr = "0x1f800000";
		display_mode_default = "panel";
		clock-names = "vpu_clkc";
		dev_name = "meson-fb";
		status = "disabled";
		compatible = "amlogic, meson-g12a";
		memory-region = <0x2a>;
		mem_size = <0x800000 0x1980000 0x100000 0x100000 0x800000>;
		clocks = <0x02 0xc9>;
		mem_alloc = <0x01>;
		interrupt-names = "viu-vsync", "viu2-vsync", "rdma";
		interrupts = <0x00 0x03 0x01 0x00 0x38 0x01 0x00 0x59 0x01>;
		scale_mode = <0x01>;
		phandle = <0xe8>;
	};

	canvas {
		dev_name = "amlogic-canvas";
		status = "okay";
		compatible = "amlogic, meson, canvas";
		reg = <0x00 0xff638000 0x00 0x2000>;
		phandle = <0xe6>;
	};

	rng {
		quality = [03 e8];
		#address-cells = <0x02>;
		status = "okay";
		compatible = "amlogic,meson-rng";
		#size-cells = <0x02>;
		reg = <0x00 0xff630218 0x00 0x04>;
	};

	venc-cvbs {
		status = "okay";
		compatible = "amlogic,meson-gxbb-cvbs";

		ports {
			#address-cells = <0x01>;
			#size-cells = <0x00>;

			port@0 {
				#address-cells = <0x01>;
				#size-cells = <0x00>;
				reg = <0x00>;
				phandle = <0x109>;
			};
		};
	};
};
